VERSION ""

NS_ :

BS_:

BU_: BSG_Master Tester
VAL_TABLE_ IN_ANA_SELECT 1 "SEL2" 0 "SEL1" ;
VAL_TABLE_ SoundID 18 "TickTock" 17 "Gong3" 16 "800Hz" 15 "1250Hz" 14 "625Hz" 13 "Clack" 12 "Click" 11 "976Hz" 10 "2200Hz" 9 "1200Hz" 8 "488Hz" 7 "FireAlarm" 6 "Gong2" 5 "Gong1" 4 "600Hz" 3 "Tick" 2 "Tock" 1 "920Hz" 0 "2800Hz" ;

BO_ 2147484928 GATEWAY_TT_Ctrl_To_IC: 8 Tester
 SG_ N_Gateway : 0|64@1+ (1,0) [0|0] ""  BSG_Master

BO_ 2147484929 GATEWAY_Gauge_Ctrl_To_IC: 8 Tester
 SG_ N_Gateway : 0|64@1+ (1,0) [0|0] ""  BSG_Master

BO_ 2147484930 GATEWAY_Illumination_Ctrl_To_IC: 8 Tester
 SG_ N_Gateway : 0|64@1+ (1,0) [0|0] ""  BSG_Master

BO_ 2147484931 GATEWAY_Sound_Ctrl_To_IC: 8 Tester
 SG_ N_Gateway : 0|64@1+ (1,0) [0|0] ""  BSG_Master

BO_ 2147484932 GATEWAY_IC_Mode_To_IC: 8 Tester
 SG_ N_Gateway : 0|64@1+ (1,0) [0|0] ""  BSG_Master

BO_ 2147485184 GATEWAY_IC_Status_From_IC: 8 BSG_Master
 SG_ N_Gateway : 0|64@1+ (1,0) [0|0] ""  Tester

BO_ 2147486465 Out_Ctrl: 8 Tester
 SG_ WorkingMode : 60|1@1+ (1,0) [0|1] "" Vector__XXX
 SG_ Out_01_Ctrl : 0|1@1+ (1,0) [0|1] ""  BSG_Master
 SG_ Out_02_Ctrl : 1|1@1+ (1,0) [0|1] ""  BSG_Master
 SG_ Out_03_Ctrl : 2|1@1+ (1,0) [0|1] ""  BSG_Master
 SG_ Out_04_Ctrl : 3|1@1+ (1,0) [0|1] ""  BSG_Master
 SG_ Out_05_Ctrl : 4|1@1+ (1,0) [0|1] ""  BSG_Master
 SG_ Out_06_Ctrl : 5|1@1+ (1,0) [0|1] ""  BSG_Master
 SG_ Out_07_Ctrl : 6|1@1+ (1,0) [0|1] ""  BSG_Master
 SG_ Out_08_Ctrl : 7|1@1+ (1,0) [0|1] ""  BSG_Master
 SG_ Out_09_Ctrl : 8|1@1+ (1,0) [0|1] ""  BSG_Master
 SG_ Out_10_Ctrl : 9|1@1+ (1,0) [0|1] ""  BSG_Master
 SG_ Out_11_Ctrl : 10|1@1+ (1,0) [0|1] ""  BSG_Master
 SG_ Out_12_Ctrl : 11|1@1+ (1,0) [0|1] ""  BSG_Master
 SG_ Out_13_Ctrl : 12|1@1+ (1,0) [0|1] ""  BSG_Master
 SG_ Out_14_Ctrl : 13|1@1+ (1,0) [0|1] ""  BSG_Master
 SG_ Out_15_Ctrl : 14|1@1+ (1,0) [0|1] ""  BSG_Master
 SG_ Out_16_Ctrl : 15|1@1+ (1,0) [0|1] ""  BSG_Master
 SG_ Out_17_Ctrl : 16|1@1+ (1,0) [0|1] ""  BSG_Master
 SG_ Out_18_PWM_Ctrl : 24|8@1+ (1,0) [0|255] ""  BSG_Master
 SG_ Out_19_Ctrl : 18|1@1+ (1,0) [0|1] ""  BSG_Master
 SG_ Out_Supply_ANA_01_Ctrl : 56|1@1+ (1,0) [0|1] ""  BSG_Master
 SG_ Out_Supply_ANA_02_Ctrl : 57|1@1+ (1,0) [0|1] ""  BSG_Master
 SG_ Out_Supply_ANA_03_Ctrl : 58|1@1+ (1,0) [0|1] ""  BSG_Master

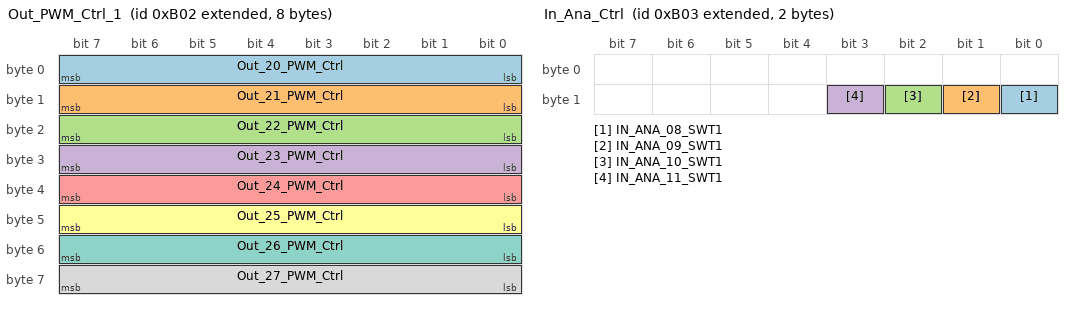
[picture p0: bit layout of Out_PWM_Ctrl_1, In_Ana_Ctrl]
BO_ 2147486466 Out_PWM_Ctrl_1: 8 Tester
 SG_ Out_20_PWM_Ctrl : 0|8@1+ (1,0) [0|255] ""  BSG_Master
 SG_ Out_21_PWM_Ctrl : 8|8@1+ (1,0) [0|255] ""  BSG_Master
 SG_ Out_22_PWM_Ctrl : 16|8@1+ (1,0) [0|255] ""  BSG_Master
 SG_ Out_23_PWM_Ctrl : 24|8@1+ (1,0) [0|255] ""  BSG_Master
 SG_ Out_24_PWM_Ctrl : 32|8@1+ (1,0) [0|255] ""  BSG_Master
 SG_ Out_25_PWM_Ctrl : 40|8@1+ (1,0) [0|255] ""  BSG_Master
 SG_ Out_26_PWM_Ctrl : 48|8@1+ (1,0) [0|255] ""  BSG_Master
 SG_ Out_27_PWM_Ctrl : 56|8@1+ (1,0) [0|255] ""  BSG_Master

BO_ 2147486467 In_Ana_Ctrl: 2 Tester
 SG_ IN_ANA_08_SWT1 : 8|1@1+ (1,0) [0|0] ""  BSG_Master
 SG_ IN_ANA_09_SWT1 : 9|1@1+ (1,0) [0|0] ""  BSG_Master
 SG_ IN_ANA_10_SWT1 : 10|1@1+ (1,0) [0|0] ""  BSG_Master
 SG_ IN_ANA_11_SWT1 : 11|1@1+ (1,0) [0|0] ""  BSG_Master

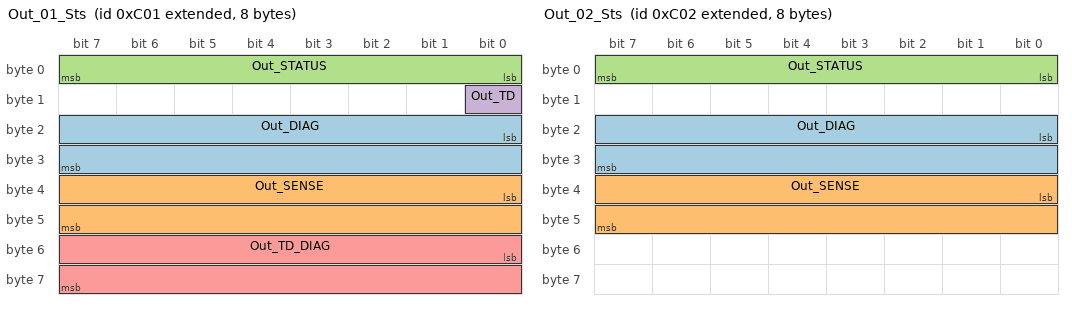
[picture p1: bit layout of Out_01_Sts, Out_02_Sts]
BO_ 2147486721 Out_01_Sts: 8 BSG_Master
 SG_ Out_DIAG : 16|16@1+ (1,0) [0|65535] ""  Tester
 SG_ Out_SENSE : 32|16@1+ (1,0) [0|65535] ""  Tester
 SG_ Out_STATUS : 0|8@1+ (1,0) [0|255] ""  Tester
 SG_ Out_TD : 8|1@1+ (1,0) [0|0] ""  Tester
 SG_ Out_TD_DIAG : 48|16@1+ (1,0) [0|0] ""  Tester

BO_ 2147486722 Out_02_Sts: 8 BSG_Master
 SG_ Out_DIAG : 16|16@1+ (1,0) [0|65535] ""  Tester
 SG_ Out_SENSE : 32|16@1+ (1,0) [0|65535] ""  Tester
 SG_ Out_STATUS : 0|8@1+ (1,0) [0|255] ""  Tester

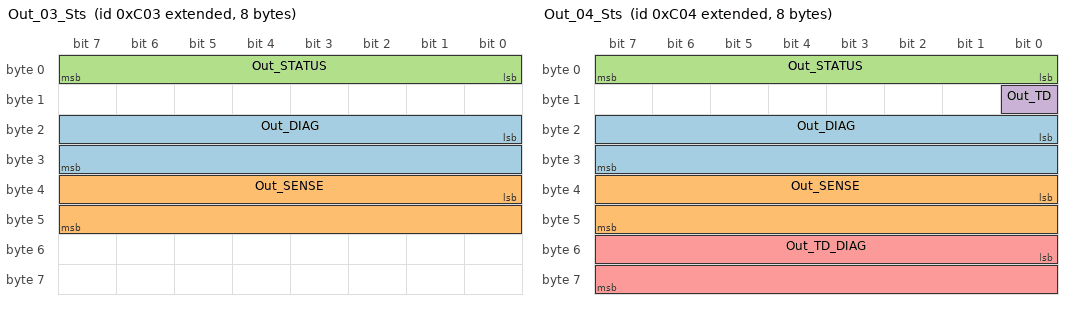
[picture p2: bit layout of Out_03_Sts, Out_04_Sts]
BO_ 2147486723 Out_03_Sts: 8 BSG_Master
 SG_ Out_DIAG : 16|16@1+ (1,0) [0|65535] ""  Tester
 SG_ Out_SENSE : 32|16@1+ (1,0) [0|65535] ""  Tester
 SG_ Out_STATUS : 0|8@1+ (1,0) [0|255] ""  Tester

BO_ 2147486724 Out_04_Sts: 8 BSG_Master
 SG_ Out_DIAG : 16|16@1+ (1,0) [0|65535] ""  Tester
 SG_ Out_SENSE : 32|16@1+ (1,0) [0|65535] ""  Tester
 SG_ Out_STATUS : 0|8@1+ (1,0) [0|255] ""  Tester
 SG_ Out_TD : 8|1@1+ (1,0) [0|0] ""  Tester
 SG_ Out_TD_DIAG : 48|16@1+ (1,0) [0|0] ""  Tester

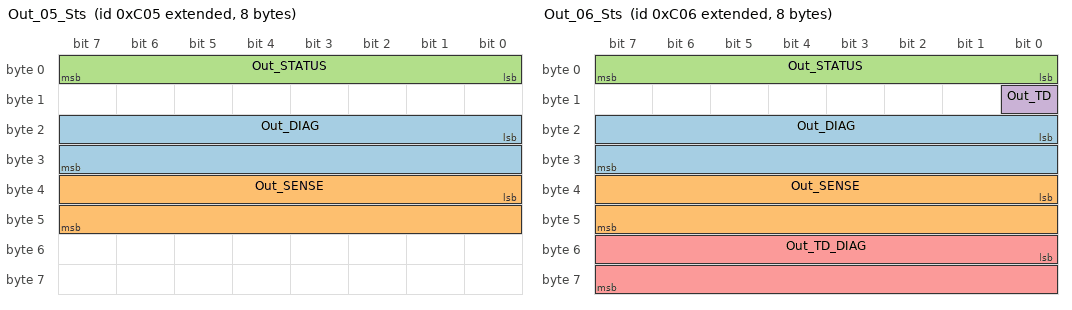
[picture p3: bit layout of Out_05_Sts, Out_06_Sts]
BO_ 2147486725 Out_05_Sts: 8 BSG_Master
 SG_ Out_DIAG : 16|16@1+ (1,0) [0|65535] ""  Tester
 SG_ Out_SENSE : 32|16@1+ (1,0) [0|65535] ""  Tester
 SG_ Out_STATUS : 0|8@1+ (1,0) [0|255] ""  Tester

BO_ 2147486726 Out_06_Sts: 8 BSG_Master
 SG_ Out_DIAG : 16|16@1+ (1,0) [0|65535] ""  Tester
 SG_ Out_SENSE : 32|16@1+ (1,0) [0|65535] ""  Tester
 SG_ Out_STATUS : 0|8@1+ (1,0) [0|255] ""  Tester
 SG_ Out_TD : 8|1@1+ (1,0) [0|0] ""  Tester
 SG_ Out_TD_DIAG : 48|16@1+ (1,0) [0|0] ""  Tester

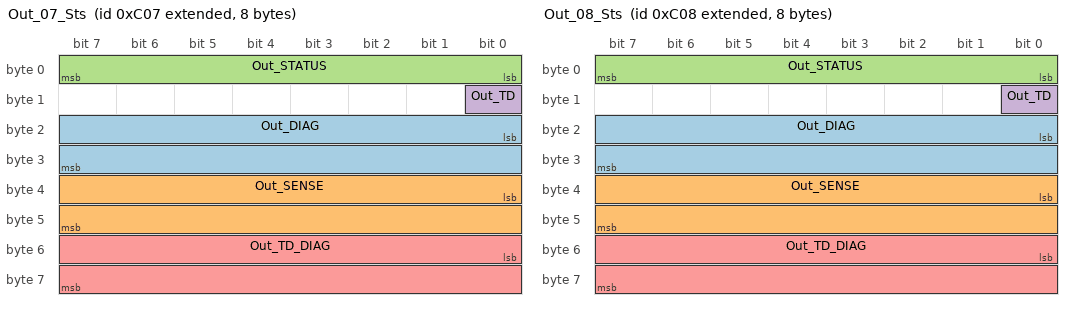
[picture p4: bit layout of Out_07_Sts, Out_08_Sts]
BO_ 2147486727 Out_07_Sts: 8 BSG_Master
 SG_ Out_DIAG : 16|16@1+ (1,0) [0|65535] ""  Tester
 SG_ Out_SENSE : 32|16@1+ (1,0) [0|65535] ""  Tester
 SG_ Out_STATUS : 0|8@1+ (1,0) [0|255] ""  Tester
 SG_ Out_TD : 8|1@1+ (1,0) [0|0] ""  Tester
 SG_ Out_TD_DIAG : 48|16@1+ (1,0) [0|0] ""  Tester

BO_ 2147486728 Out_08_Sts: 8 BSG_Master
 SG_ Out_DIAG : 16|16@1+ (1,0) [0|65535] ""  Tester
 SG_ Out_SENSE : 32|16@1+ (1,0) [0|65535] ""  Tester
 SG_ Out_STATUS : 0|8@1+ (1,0) [0|255] ""  Tester
 SG_ Out_TD : 8|1@1+ (1,0) [0|0] ""  Tester
 SG_ Out_TD_DIAG : 48|16@1+ (1,0) [0|0] ""  Tester

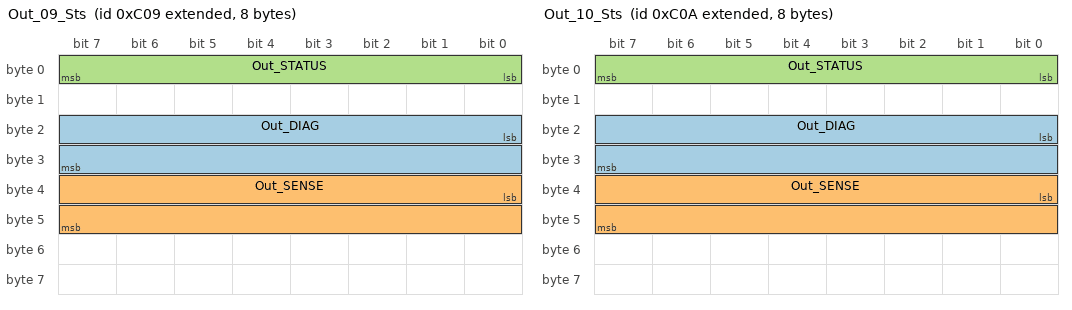
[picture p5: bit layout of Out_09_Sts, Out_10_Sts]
BO_ 2147486729 Out_09_Sts: 8 BSG_Master
 SG_ Out_DIAG : 16|16@1+ (1,0) [0|65535] ""  Tester
 SG_ Out_SENSE : 32|16@1+ (1,0) [0|65535] ""  Tester
 SG_ Out_STATUS : 0|8@1+ (1,0) [0|255] ""  Tester

BO_ 2147486730 Out_10_Sts: 8 BSG_Master
 SG_ Out_DIAG : 16|16@1+ (1,0) [0|65535] ""  Tester
 SG_ Out_SENSE : 32|16@1+ (1,0) [0|65535] ""  Tester
 SG_ Out_STATUS : 0|8@1+ (1,0) [0|255] ""  Tester

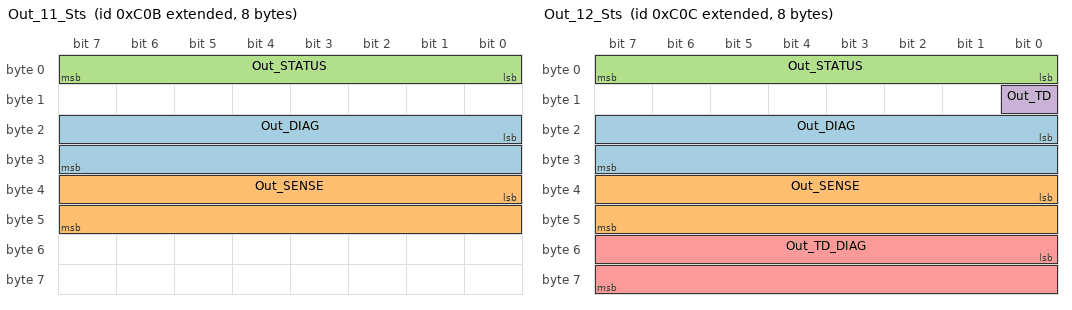
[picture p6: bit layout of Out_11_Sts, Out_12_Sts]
BO_ 2147486731 Out_11_Sts: 8 BSG_Master
 SG_ Out_DIAG : 16|16@1+ (1,0) [0|65535] ""  Tester
 SG_ Out_SENSE : 32|16@1+ (1,0) [0|65535] ""  Tester
 SG_ Out_STATUS : 0|8@1+ (1,0) [0|255] ""  Tester

BO_ 2147486732 Out_12_Sts: 8 BSG_Master
 SG_ Out_DIAG : 16|16@1+ (1,0) [0|65535] ""  Tester
 SG_ Out_SENSE : 32|16@1+ (1,0) [0|65535] ""  Tester
 SG_ Out_STATUS : 0|8@1+ (1,0) [0|255] ""  Tester
 SG_ Out_TD : 8|1@1+ (1,0) [0|0] ""  Tester
 SG_ Out_TD_DIAG : 48|16@1+ (1,0) [0|0] ""  Tester

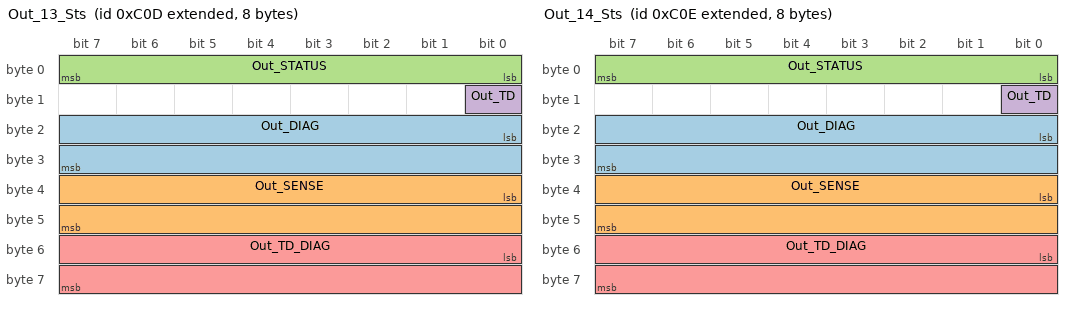
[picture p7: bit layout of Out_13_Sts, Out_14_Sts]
BO_ 2147486733 Out_13_Sts: 8 BSG_Master
 SG_ Out_DIAG : 16|16@1+ (1,0) [0|65535] ""  Tester
 SG_ Out_SENSE : 32|16@1+ (1,0) [0|65535] ""  Tester
 SG_ Out_STATUS : 0|8@1+ (1,0) [0|255] ""  Tester
 SG_ Out_TD : 8|1@1+ (1,0) [0|0] ""  Tester
 SG_ Out_TD_DIAG : 48|16@1+ (1,0) [0|0] ""  Tester

BO_ 2147486734 Out_14_Sts: 8 BSG_Master
 SG_ Out_DIAG : 16|16@1+ (1,0) [0|65535] ""  Tester
 SG_ Out_SENSE : 32|16@1+ (1,0) [0|65535] ""  Tester
 SG_ Out_STATUS : 0|8@1+ (1,0) [0|255] ""  Tester
 SG_ Out_TD : 8|1@1+ (1,0) [0|0] ""  Tester
 SG_ Out_TD_DIAG : 48|16@1+ (1,0) [0|0] ""  Tester

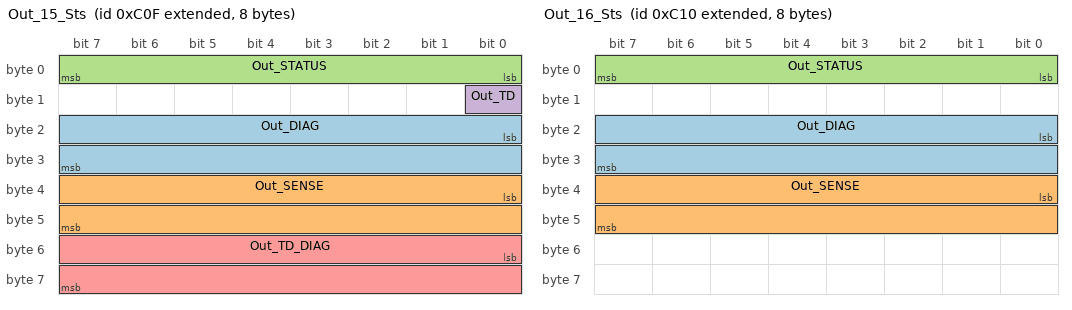
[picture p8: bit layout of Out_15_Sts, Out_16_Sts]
BO_ 2147486735 Out_15_Sts: 8 BSG_Master
 SG_ Out_DIAG : 16|16@1+ (1,0) [0|65535] ""  Tester
 SG_ Out_SENSE : 32|16@1+ (1,0) [0|65535] ""  Tester
 SG_ Out_STATUS : 0|8@1+ (1,0) [0|255] ""  Tester
 SG_ Out_TD : 8|1@1+ (1,0) [0|0] ""  Tester
 SG_ Out_TD_DIAG : 48|16@1+ (1,0) [0|0] ""  Tester

BO_ 2147486736 Out_16_Sts: 8 BSG_Master
 SG_ Out_DIAG : 16|16@1+ (1,0) [0|65535] ""  Tester
 SG_ Out_SENSE : 32|16@1+ (1,0) [0|65535] ""  Tester
 SG_ Out_STATUS : 0|8@1+ (1,0) [0|255] ""  Tester

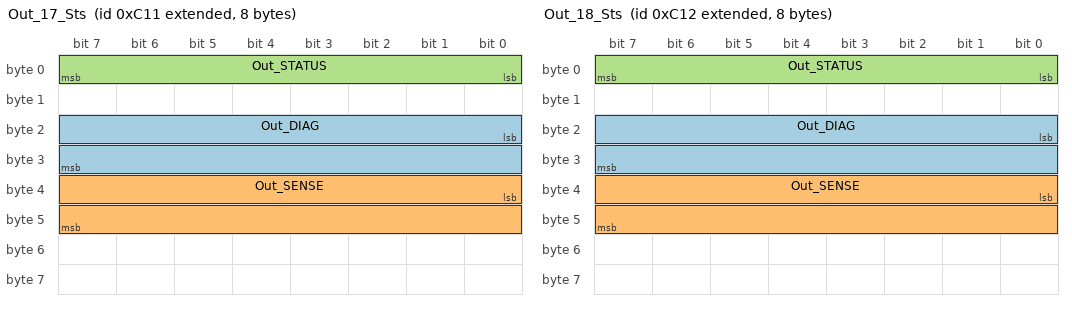
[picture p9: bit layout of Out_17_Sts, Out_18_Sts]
BO_ 2147486737 Out_17_Sts: 8 BSG_Master
 SG_ Out_DIAG : 16|16@1+ (1,0) [0|65535] ""  Tester
 SG_ Out_SENSE : 32|16@1+ (1,0) [0|65535] ""  Tester
 SG_ Out_STATUS : 0|8@1+ (1,0) [0|255] ""  Tester

BO_ 2147486738 Out_18_Sts: 8 BSG_Master
 SG_ Out_DIAG : 16|16@1+ (1,0) [0|65535] ""  Tester
 SG_ Out_SENSE : 32|16@1+ (1,0) [0|65535] ""  Tester
 SG_ Out_STATUS : 0|8@1+ (1,0) [0|255] ""  Tester

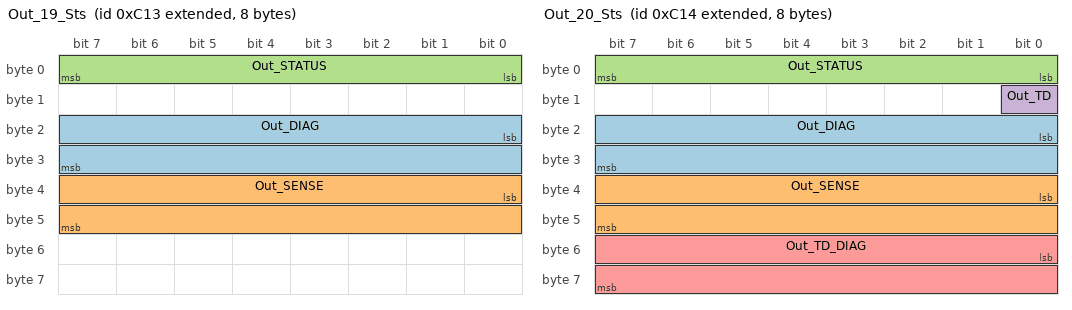
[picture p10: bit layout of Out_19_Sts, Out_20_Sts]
BO_ 2147486739 Out_19_Sts: 8 BSG_Master
 SG_ Out_DIAG : 16|16@1+ (1,0) [0|65535] ""  Tester
 SG_ Out_SENSE : 32|16@1+ (1,0) [0|65535] ""  Tester
 SG_ Out_STATUS : 0|8@1+ (1,0) [0|255] ""  Tester

BO_ 2147486740 Out_20_Sts: 8 BSG_Master
 SG_ Out_DIAG : 16|16@1+ (1,0) [0|65535] ""  Tester
 SG_ Out_SENSE : 32|16@1+ (1,0) [0|65535] ""  Tester
 SG_ Out_STATUS : 0|8@1+ (1,0) [0|255] ""  Tester
 SG_ Out_TD : 8|1@1+ (1,0) [0|0] ""  Tester
 SG_ Out_TD_DIAG : 48|16@1+ (1,0) [0|0] ""  Tester

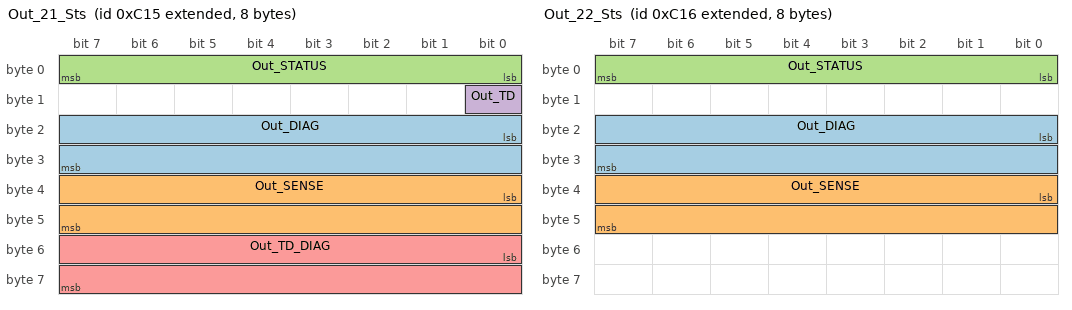
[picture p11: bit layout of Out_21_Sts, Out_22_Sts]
BO_ 2147486741 Out_21_Sts: 8 BSG_Master
 SG_ Out_DIAG : 16|16@1+ (1,0) [0|65535] ""  Tester
 SG_ Out_SENSE : 32|16@1+ (1,0) [0|65535] ""  Tester
 SG_ Out_STATUS : 0|8@1+ (1,0) [0|255] ""  Tester
 SG_ Out_TD : 8|1@1+ (1,0) [0|0] ""  Tester
 SG_ Out_TD_DIAG : 48|16@1+ (1,0) [0|0] ""  Tester

BO_ 2147486742 Out_22_Sts: 8 BSG_Master
 SG_ Out_DIAG : 16|16@1+ (1,0) [0|65535] ""  Tester
 SG_ Out_SENSE : 32|16@1+ (1,0) [0|65535] ""  Tester
 SG_ Out_STATUS : 0|8@1+ (1,0) [0|255] ""  Tester

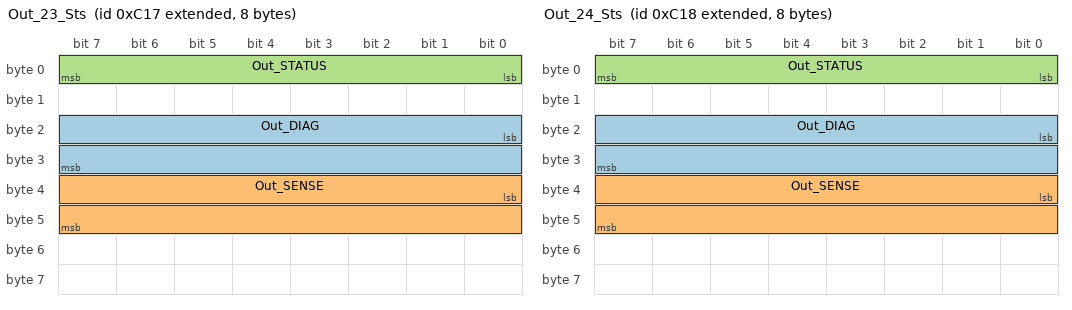
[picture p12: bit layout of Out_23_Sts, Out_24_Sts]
BO_ 2147486743 Out_23_Sts: 8 BSG_Master
 SG_ Out_DIAG : 16|16@1+ (1,0) [0|65535] ""  Tester
 SG_ Out_SENSE : 32|16@1+ (1,0) [0|65535] ""  Tester
 SG_ Out_STATUS : 0|8@1+ (1,0) [0|255] ""  Tester

BO_ 2147486744 Out_24_Sts: 8 BSG_Master
 SG_ Out_DIAG : 16|16@1+ (1,0) [0|65535] ""  Tester
 SG_ Out_SENSE : 32|16@1+ (1,0) [0|65535] ""  Tester
 SG_ Out_STATUS : 0|8@1+ (1,0) [0|255] ""  Tester

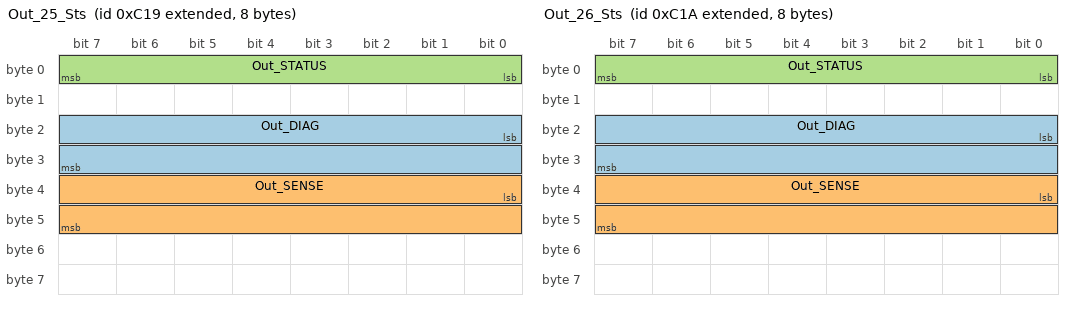
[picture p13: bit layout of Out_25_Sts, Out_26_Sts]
BO_ 2147486745 Out_25_Sts: 8 BSG_Master
 SG_ Out_DIAG : 16|16@1+ (1,0) [0|65535] ""  Tester
 SG_ Out_SENSE : 32|16@1+ (1,0) [0|65535] ""  Tester
 SG_ Out_STATUS : 0|8@1+ (1,0) [0|255] ""  Tester

BO_ 2147486746 Out_26_Sts: 8 BSG_Master
 SG_ Out_DIAG : 16|16@1+ (1,0) [0|65535] ""  Tester
 SG_ Out_SENSE : 32|16@1+ (1,0) [0|65535] ""  Tester
 SG_ Out_STATUS : 0|8@1+ (1,0) [0|255] ""  Tester

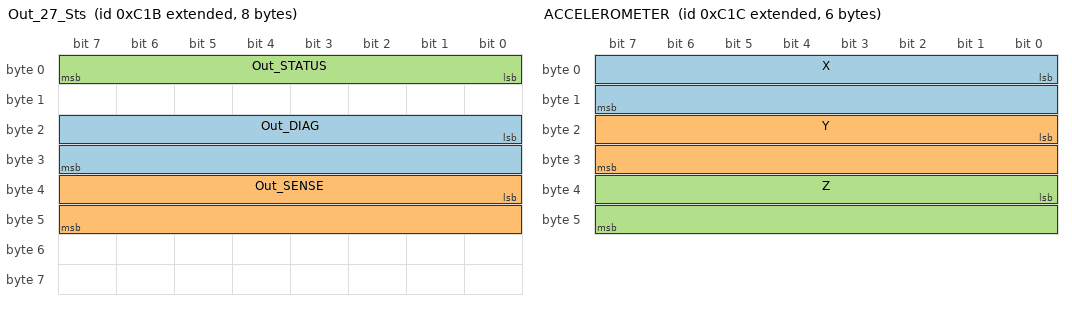
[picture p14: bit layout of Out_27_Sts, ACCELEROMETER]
BO_ 2147486747 Out_27_Sts: 8 BSG_Master
 SG_ Out_DIAG : 16|16@1+ (1,0) [0|65535] ""  Tester
 SG_ Out_SENSE : 32|16@1+ (1,0) [0|65535] ""  Tester
 SG_ Out_STATUS : 0|8@1+ (1,0) [0|255] ""  Tester

BO_ 2147486748 ACCELEROMETER: 6 BSG_Master
 SG_ X : 0|16@1- (1,0) [0|0] ""  Tester
 SG_ Y : 16|16@1- (1,0) [0|0] ""  Tester
 SG_ Z : 32|16@1- (1,0) [0|0] ""  Tester

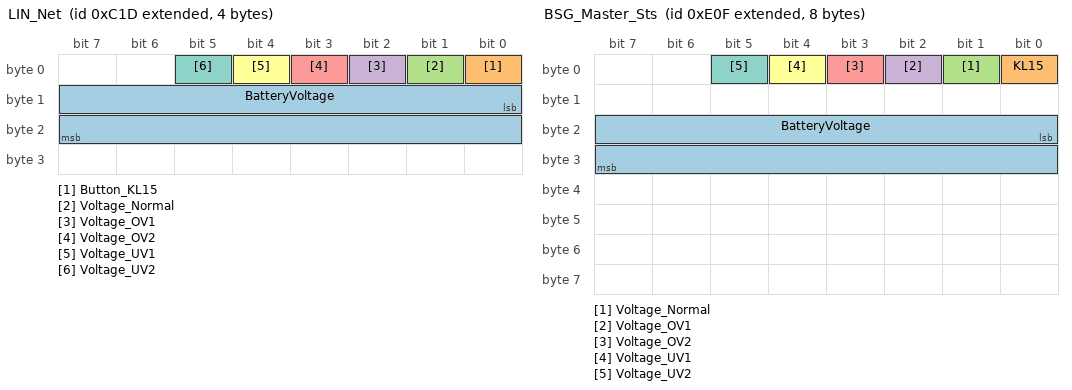
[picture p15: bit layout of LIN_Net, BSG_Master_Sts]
BO_ 2147486749 LIN_Net: 4 BSG_Master
 SG_ BatteryVoltage : 8|16@1+ (1,0) [0|0] ""  Tester
 SG_ Button_KL15 : 0|1@1+ (1,0) [0|0] ""  Tester
 SG_ Voltage_Normal : 1|1@1+ (1,0) [0|0] ""  Tester
 SG_ Voltage_OV1 : 2|1@1+ (1,0) [0|0] ""  Tester
 SG_ Voltage_OV2 : 3|1@1+ (1,0) [0|0] ""  Tester
 SG_ Voltage_UV1 : 4|1@1+ (1,0) [0|1] ""  Tester
 SG_ Voltage_UV2 : 5|1@1+ (1,0) [0|1] ""  Tester

BO_ 2147486750 Out_Supply_ANA_01_Sts: 8 BSG_Master
 SG_ Supply_ANA_DIAG : 16|16@1+ (1,0) [0|65535] ""  Tester
 SG_ Supply_ANA_Val : 0|16@1+ (1,0) [0|65535] ""  Tester

BO_ 2147486751 Out_Supply_ANA_02_Sts: 8 BSG_Master
 SG_ Supply_ANA_DIAG : 16|16@1+ (1,0) [0|65535] ""  Tester
 SG_ Supply_ANA_Val : 0|16@1+ (1,0) [0|65535] ""  Tester

BO_ 2147486752 Out_Supply_ANA_03_Sts: 8 BSG_Master
 SG_ Supply_ANA_DIAG : 16|16@1+ (1,0) [0|65535] ""  Tester
 SG_ Supply_ANA_Val : 0|16@1+ (1,0) [0|65535] ""  Tester

BO_ 2147486977 In_Dig_01_Sts: 8 BSG_Master
 SG_ IN_DIG_DIAG : 16|16@1+ (1,0) [0|65535] ""  Tester
 SG_ IN_DIG_Val : 0|1@1+ (1,0) [0|1] ""  Tester

BO_ 2147486978 In_Dig_02_Sts: 8 BSG_Master
 SG_ IN_DIG_DIAG : 16|16@1+ (1,0) [0|65535] ""  Tester
 SG_ IN_DIG_Val : 0|1@1+ (1,0) [0|1] ""  Tester

BO_ 2147486979 In_Dig_03_Sts: 8 BSG_Master
 SG_ IN_DIG_DIAG : 16|16@1+ (1,0) [0|65535] ""  Tester
 SG_ IN_DIG_Val : 0|1@1+ (1,0) [0|1] ""  Tester

BO_ 2147486980 In_Dig_04_Sts: 8 BSG_Master
 SG_ IN_DIG_DIAG : 16|16@1+ (1,0) [0|65535] ""  Tester
 SG_ IN_DIG_Val : 0|1@1+ (1,0) [0|1] ""  Tester

BO_ 2147486981 In_Dig_05_Sts: 8 BSG_Master
 SG_ IN_DIG_DIAG : 16|16@1+ (1,0) [0|65535] ""  Tester
 SG_ IN_DIG_Val : 0|1@1+ (1,0) [0|1] ""  Tester

BO_ 2147486982 In_Dig_06_Sts: 8 BSG_Master
 SG_ IN_DIG_DIAG : 16|16@1+ (1,0) [0|65535] ""  Tester
 SG_ IN_DIG_Val : 0|1@1+ (1,0) [0|1] ""  Tester

BO_ 2147486983 In_Dig_07_Sts: 8 BSG_Master
 SG_ IN_DIG_DIAG : 16|16@1+ (1,0) [0|65535] ""  Tester
 SG_ IN_DIG_Val : 0|1@1+ (1,0) [0|1] ""  Tester

BO_ 2147486984 In_Dig_08_Sts: 8 BSG_Master
 SG_ IN_DIG_DIAG : 16|16@1+ (1,0) [0|65535] ""  Tester
 SG_ IN_DIG_Val : 0|1@1+ (1,0) [0|1] ""  Tester

BO_ 2147486985 In_Dig_09_Sts: 8 BSG_Master
 SG_ IN_DIG_DIAG : 16|16@1+ (1,0) [0|65535] ""  Tester
 SG_ IN_DIG_Val : 0|1@1+ (1,0) [0|1] ""  Tester

BO_ 2147486986 In_Dig_10_Sts: 8 BSG_Master
 SG_ IN_DIG_DIAG : 16|16@1+ (1,0) [0|65535] ""  Tester
 SG_ IN_DIG_Val : 0|1@1+ (1,0) [0|1] ""  Tester

BO_ 2147486987 In_Dig_11_Sts: 8 BSG_Master
 SG_ IN_DIG_DIAG : 16|16@1+ (1,0) [0|65535] ""  Tester
 SG_ IN_DIG_Val : 0|1@1+ (1,0) [0|1] ""  Tester

BO_ 2147486988 In_Dig_12_Sts: 8 BSG_Master
 SG_ IN_DIG_DIAG : 16|16@1+ (1,0) [0|65535] ""  Tester
 SG_ IN_DIG_Val : 0|1@1+ (1,0) [0|1] ""  Tester

BO_ 2147486989 In_Dig_13_Sts: 8 BSG_Master
 SG_ IN_DIG_DIAG : 16|16@1+ (1,0) [0|65535] ""  Tester
 SG_ IN_DIG_Val : 0|1@1+ (1,0) [0|1] ""  Tester

BO_ 2147486990 In_Dig_14_Sts: 8 BSG_Master
 SG_ IN_DIG_DIAG : 16|16@1+ (1,0) [0|65535] ""  Tester
 SG_ IN_DIG_Val : 0|1@1+ (1,0) [0|1] ""  Tester

BO_ 2147486991 In_Dig_15_Sts: 8 BSG_Master
 SG_ IN_DIG_DIAG : 16|16@1+ (1,0) [0|65535] ""  Tester
 SG_ IN_DIG_Val : 0|1@1+ (1,0) [0|1] ""  Tester

BO_ 2147486992 In_Dig_16_Sts: 8 BSG_Master
 SG_ IN_DIG_DIAG : 16|16@1+ (1,0) [0|65535] ""  Tester
 SG_ IN_DIG_Val : 0|1@1+ (1,0) [0|1] ""  Tester

BO_ 2147486993 In_Dig_17_Sts: 8 BSG_Master
 SG_ IN_DIG_DIAG : 16|16@1+ (1,0) [0|65535] ""  Tester
 SG_ IN_DIG_Val : 0|1@1+ (1,0) [0|1] ""  Tester

BO_ 2147486994 In_Dig_18_Sts: 8 BSG_Master
 SG_ IN_DIG_DIAG : 16|16@1+ (1,0) [0|65535] ""  Tester
 SG_ IN_DIG_Val : 0|1@1+ (1,0) [0|1] ""  Tester

BO_ 2147486995 In_Dig_19_Sts: 8 BSG_Master
 SG_ IN_DIG_DIAG : 16|16@1+ (1,0) [0|65535] ""  Tester
 SG_ IN_DIG_Val : 0|1@1+ (1,0) [0|1] ""  Tester

BO_ 2147486996 In_Dig_20_Sts: 8 BSG_Master
 SG_ IN_DIG_DIAG : 16|16@1+ (1,0) [0|65535] ""  Tester
 SG_ IN_DIG_Val : 0|1@1+ (1,0) [0|1] ""  Tester

BO_ 2147486997 In_Dig_21_Sts: 8 BSG_Master
 SG_ IN_DIG_DIAG : 16|16@1+ (1,0) [0|65535] ""  Tester
 SG_ IN_DIG_Val : 0|1@1+ (1,0) [0|1] ""  Tester

BO_ 2147486998 In_Dig_22_Sts: 8 BSG_Master
 SG_ IN_DIG_DIAG : 16|16@1+ (1,0) [0|65535] ""  Tester
 SG_ IN_DIG_Val : 0|1@1+ (1,0) [0|1] ""  Tester

BO_ 2147486999 In_Dig_23_Sts: 8 BSG_Master
 SG_ IN_DIG_DIAG : 16|16@1+ (1,0) [0|65535] ""  Tester
 SG_ IN_DIG_Val : 0|1@1+ (1,0) [0|1] ""  Tester

BO_ 2147487000 In_Dig_24_Sts: 8 BSG_Master
 SG_ IN_DIG_DIAG : 16|16@1+ (1,0) [0|65535] ""  Tester
 SG_ IN_DIG_Val : 0|1@1+ (1,0) [0|1] ""  Tester

BO_ 2147487001 In_Dig_25_Sts: 8 BSG_Master
 SG_ IN_DIG_DIAG : 16|16@1+ (1,0) [0|65535] ""  Tester
 SG_ IN_DIG_Val : 0|1@1+ (1,0) [0|1] ""  Tester

BO_ 2147487002 In_Dig_26_Sts: 8 BSG_Master
 SG_ IN_DIG_DIAG : 16|16@1+ (1,0) [0|65535] ""  Tester
 SG_ IN_DIG_Val : 0|1@1+ (1,0) [0|1] ""  Tester

BO_ 2147487003 In_Dig_27_Sts: 8 BSG_Master
 SG_ IN_DIG_DIAG : 16|16@1+ (1,0) [0|65535] ""  Tester
 SG_ IN_DIG_Val : 0|1@1+ (1,0) [0|1] ""  Tester

BO_ 2147487004 In_Dig_28_Sts: 8 BSG_Master
 SG_ IN_DIG_DIAG : 16|16@1+ (1,0) [0|65535] ""  Tester
 SG_ IN_DIG_Val : 0|1@1+ (1,0) [0|1] ""  Tester

BO_ 2147487005 In_Dig_29_Sts: 8 BSG_Master
 SG_ IN_DIG_DIAG : 16|16@1+ (1,0) [0|65535] ""  Tester
 SG_ IN_DIG_Val : 0|1@1+ (1,0) [0|1] ""  Tester

BO_ 2147487006 In_Dig_30_Sts: 8 BSG_Master
 SG_ IN_DIG_DIAG : 16|16@1+ (1,0) [0|65535] ""  Tester
 SG_ IN_DIG_Val : 0|1@1+ (1,0) [0|1] ""  Tester

BO_ 2147487007 In_Dig_31_Sts: 8 BSG_Master
 SG_ IN_DIG_DIAG : 16|16@1+ (1,0) [0|65535] ""  Tester
 SG_ IN_DIG_Val : 0|1@1+ (1,0) [0|1] ""  Tester

BO_ 2147487008 In_Dig_32_Sts: 8 BSG_Master
 SG_ IN_DIG_DIAG : 16|16@1+ (1,0) [0|65535] ""  Tester
 SG_ IN_DIG_Val : 0|1@1+ (1,0) [0|1] ""  Tester

BO_ 2147487009 In_Dig_33_Sts: 8 BSG_Master
 SG_ IN_DIG_DIAG : 16|16@1+ (1,0) [0|65535] ""  Tester
 SG_ IN_DIG_Val : 0|1@1+ (1,0) [0|1] ""  Tester

BO_ 2147487010 In_Dig_34_Sts: 8 BSG_Master
 SG_ IN_DIG_DIAG : 16|16@1+ (1,0) [0|65535] ""  Tester
 SG_ IN_DIG_Val : 0|1@1+ (1,0) [0|1] ""  Tester

BO_ 2147487011 In_Dig_35_Sts: 8 BSG_Master
 SG_ IN_DIG_DIAG : 16|16@1+ (1,0) [0|65535] ""  Tester
 SG_ IN_DIG_Val : 0|1@1+ (1,0) [0|1] ""  Tester

BO_ 2147487012 In_Dig_36_Sts: 8 BSG_Master
 SG_ IN_DIG_DIAG : 16|16@1+ (1,0) [0|65535] ""  Tester
 SG_ IN_DIG_Val : 0|1@1+ (1,0) [0|1] ""  Tester

BO_ 2147487013 In_Dig_37_Sts: 8 BSG_Master
 SG_ IN_DIG_DIAG : 16|16@1+ (1,0) [0|65535] ""  Tester
 SG_ IN_DIG_Val : 0|1@1+ (1,0) [0|1] ""  Tester

BO_ 2147487014 In_Dig_38_Sts: 8 BSG_Master
 SG_ IN_DIG_DIAG : 16|16@1+ (1,0) [0|65535] ""  Tester
 SG_ IN_DIG_Val : 0|1@1+ (1,0) [0|1] ""  Tester

BO_ 2147487015 In_Dig_39_Sts: 8 BSG_Master
 SG_ IN_DIG_DIAG : 16|16@1+ (1,0) [0|65535] ""  Tester
 SG_ IN_DIG_Val : 0|1@1+ (1,0) [0|1] ""  Tester

BO_ 2147487016 In_Dig_40_Sts: 8 BSG_Master
 SG_ IN_DIG_DIAG : 16|16@1+ (1,0) [0|65535] ""  Tester
 SG_ IN_DIG_Val : 0|1@1+ (1,0) [0|1] ""  Tester

BO_ 2147487017 In_Dig_41_Sts: 8 BSG_Master
 SG_ IN_DIG_DIAG : 16|16@1+ (1,0) [0|65535] ""  Tester
 SG_ IN_DIG_Val : 0|1@1+ (1,0) [0|1] ""  Tester

BO_ 2147487018 In_Dig_42_Sts: 8 BSG_Master
 SG_ IN_DIG_DIAG : 16|16@1+ (1,0) [0|65535] ""  Tester
 SG_ IN_DIG_Val : 0|1@1+ (1,0) [0|1] ""  Tester

BO_ 2147487019 In_Dig_43_Sts: 8 BSG_Master
 SG_ IN_DIG_DIAG : 16|16@1+ (1,0) [0|65535] ""  Tester
 SG_ IN_DIG_Val : 0|1@1+ (1,0) [0|1] ""  Tester

BO_ 2147487020 In_Dig_44_Sts: 8 BSG_Master
 SG_ IN_DIG_DIAG : 16|16@1+ (1,0) [0|65535] ""  Tester
 SG_ IN_DIG_Val : 0|1@1+ (1,0) [0|1] ""  Tester

BO_ 2147487021 In_Dig_45_Sts: 8 BSG_Master
 SG_ IN_DIG_DIAG : 16|16@1+ (1,0) [0|65535] ""  Tester
 SG_ IN_DIG_Val : 0|1@1+ (1,0) [0|1] ""  Tester

BO_ 2147487022 In_Dig_46_Sts: 8 BSG_Master
 SG_ IN_DIG_DIAG : 16|16@1+ (1,0) [0|65535] ""  Tester
 SG_ IN_DIG_Val : 0|1@1+ (1,0) [0|1] ""  Tester

BO_ 2147487024 In_Dig_48_Sts: 8 BSG_Master
 SG_ IN_DIG_DIAG : 16|16@1+ (1,0) [0|65535] ""  Tester
 SG_ IN_DIG_Val : 0|1@1+ (1,0) [0|1] ""  Tester

BO_ 2147487025 In_Dig_49_Sts: 8 BSG_Master
 SG_ IN_DIG_DIAG : 16|16@1+ (1,0) [0|65535] ""  Tester
 SG_ IN_DIG_Val : 0|1@1+ (1,0) [0|1] ""  Tester

BO_ 2147487026 In_Dig_50_Sts: 8 BSG_Master
 SG_ IN_DIG_DIAG : 16|16@1+ (1,0) [0|65535] ""  Tester
 SG_ IN_DIG_Val : 0|1@1+ (1,0) [0|1] ""  Tester

BO_ 2147487232 PWR_Sts: 8 BSG_Master
 SG_ PWR_DIAG : 32|16@1+ (1,0) [0|65535] ""  Tester
 SG_ PWR_Val : 0|32@1+ (1,0) [0|4294967295] ""  Tester

BO_ 2147487233 PWR_G1_Sts: 8 BSG_Master
 SG_ PWR_Gx_DIAG : 16|16@1+ (1,0) [0|65535] ""  Tester
 SG_ PWR_Gx_Val : 0|16@1+ (1,0) [0|65535] ""  Tester

BO_ 2147487234 PWR_G2_Sts: 8 BSG_Master
 SG_ PWR_Gx_DIAG : 16|16@1+ (1,0) [0|65535] ""  Tester
 SG_ PWR_Gx_Val : 0|16@1+ (1,0) [0|65535] ""  Tester

BO_ 2147487235 PWR_G3_Sts: 8 BSG_Master
 SG_ PWR_Gx_DIAG : 16|16@1+ (1,0) [0|65535] ""  Tester
 SG_ PWR_Gx_Val : 0|16@1+ (1,0) [0|65535] ""  Tester

BO_ 2147487236 PWR_G4_Sts: 8 BSG_Master
 SG_ PWR_Gx_DIAG : 16|16@1+ (1,0) [0|65535] ""  Tester
 SG_ PWR_Gx_Val : 0|16@1+ (1,0) [0|65535] ""  Tester

BO_ 2147487237 PWR_G5_Sts: 8 BSG_Master
 SG_ PWR_Gx_DIAG : 16|16@1+ (1,0) [0|65535] ""  Tester
 SG_ PWR_Gx_Val : 0|16@1+ (1,0) [0|65535] ""  Tester

BO_ 2147487239 PWR_G7_Sts: 8 BSG_Master
 SG_ PWR_Gx_DIAG : 16|16@1+ (1,0) [0|65535] ""  Tester
 SG_ PWR_Gx_Val : 0|16@1+ (1,0) [0|65535] ""  Tester

BO_ 2147487247 BSG_Master_Sts: 8 BSG_Master
 SG_ BatteryVoltage : 16|16@1+ (1,0) [0|65535] ""  Tester
 SG_ KL15 : 0|1@1+ (1,0) [0|1] ""  Tester
 SG_ Voltage_Normal : 1|1@1+ (1,0) [0|1] ""  Tester
 SG_ Voltage_OV1 : 2|1@1+ (1,0) [0|1] ""  Tester
 SG_ Voltage_OV2 : 3|1@1+ (1,0) [0|1] ""  Tester
 SG_ Voltage_UV1 : 4|1@1+ (1,0) [0|1] ""  Tester
 SG_ Voltage_UV2 : 5|1@1+ (1,0) [0|1] ""  Tester

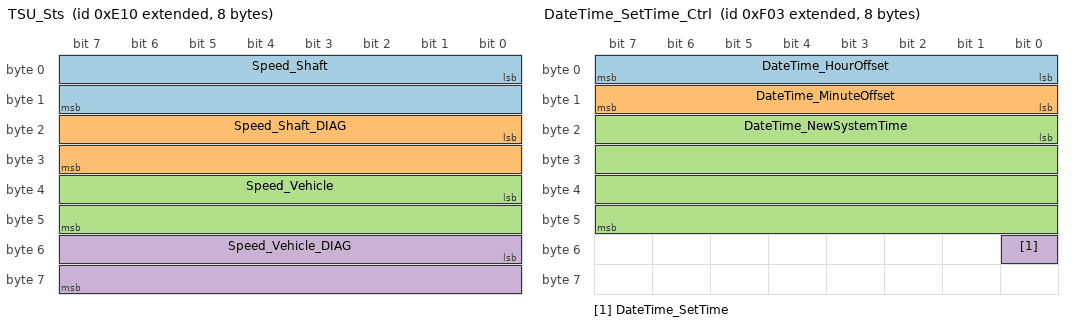
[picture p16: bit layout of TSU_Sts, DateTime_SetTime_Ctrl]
BO_ 2147487248 TSU_Sts: 8 BSG_Master
 SG_ Speed_Shaft : 0|16@1+ (1,0) [0|65535] ""  Tester
 SG_ Speed_Shaft_DIAG : 16|16@1+ (1,0) [0|65535] ""  Tester
 SG_ Speed_Vehicle : 32|16@1+ (1,0) [0|65535] ""  Tester
 SG_ Speed_Vehicle_DIAG : 48|16@1+ (1,0) [0|65535] ""  Tester

BO_ 2147487249 In_Ana_01_Sts: 8 BSG_Master
 SG_ IN_ANA_DIAG : 32|16@1+ (1,0) [0|65535] ""  Tester
 SG_ IN_ANA_Val : 0|32@1+ (1,0) [0|4294967295] ""  Tester

BO_ 2147487250 In_Ana_02_Sts: 8 BSG_Master
 SG_ IN_ANA_DIAG : 32|16@1+ (1,0) [0|65535] ""  Tester
 SG_ IN_ANA_Val : 0|32@1+ (1,0) [0|4294967295] ""  Tester

BO_ 2147487251 In_Ana_03_Sts: 8 BSG_Master
 SG_ IN_ANA_DIAG : 32|16@1+ (1,0) [0|65535] ""  Tester
 SG_ IN_ANA_Val : 0|32@1+ (1,0) [0|4294967295] ""  Tester

BO_ 2147487252 In_Ana_04_Sts: 8 BSG_Master
 SG_ IN_ANA_DIAG : 32|16@1+ (1,0) [0|65535] ""  Tester
 SG_ IN_ANA_Val : 0|32@1+ (1,0) [0|4294967295] ""  Tester

BO_ 2147487253 In_Ana_05_Sts: 8 BSG_Master
 SG_ IN_ANA_DIAG : 32|16@1+ (1,0) [0|65535] ""  Tester
 SG_ IN_ANA_Val : 0|32@1+ (1,0) [0|4294967295] ""  Tester

BO_ 2147487254 In_Ana_06_Sts: 8 BSG_Master
 SG_ IN_ANA_DIAG : 32|16@1+ (1,0) [0|65535] ""  Tester
 SG_ IN_ANA_Val : 0|32@1+ (1,0) [0|4294967295] ""  Tester

BO_ 2147487255 In_Ana_07_Sts: 8 BSG_Master
 SG_ IN_ANA_DIAG : 32|16@1+ (1,0) [0|65535] ""  Tester
 SG_ IN_ANA_Val : 0|32@1+ (1,0) [0|4294967295] ""  Tester

BO_ 2147487256 IN_ANA_08_SEL1_Sts: 8 BSG_Master
 SG_ IN_ANA_DIAG : 32|16@1+ (1,0) [0|65535] ""  Tester
 SG_ IN_ANA_Val : 0|32@1+ (1,0) [0|4294967295] ""  Tester

BO_ 2147487257 IN_ANA_09_SEL1_Sts: 8 BSG_Master
 SG_ IN_ANA_DIAG : 32|16@1+ (1,0) [0|65535] ""  Tester
 SG_ IN_ANA_Val : 0|32@1+ (1,0) [0|4294967295] ""  Tester

BO_ 2147487258 IN_ANA_10_SEL1_Sts: 8 BSG_Master
 SG_ IN_ANA_DIAG : 32|16@1+ (1,0) [0|65535] ""  Tester
 SG_ IN_ANA_Val : 0|32@1+ (1,0) [0|4294967295] ""  Tester

BO_ 2147487259 IN_ANA_11_SEL1_Sts: 8 BSG_Master
 SG_ IN_ANA_DIAG : 32|16@1+ (1,0) [0|65535] ""  Tester
 SG_ IN_ANA_Val : 0|32@1+ (1,0) [0|4294967295] ""  Tester

BO_ 2147487260 In_Ana_12_Sts: 8 BSG_Master
 SG_ IN_ANA_DIAG : 32|16@1+ (1,0) [0|65535] ""  Tester
 SG_ IN_ANA_Val : 0|32@1+ (1,0) [0|4294967295] ""  Tester

BO_ 2147487261 In_Ana_13_Sts: 8 BSG_Master
 SG_ IN_ANA_DIAG : 32|16@1+ (1,0) [0|65535] ""  Tester
 SG_ IN_ANA_Val : 0|32@1+ (1,0) [0|4294967295] ""  Tester

BO_ 2147487262 In_Ana_14_Sts: 8 BSG_Master
 SG_ IN_ANA_DIAG : 32|16@1+ (1,0) [0|65535] ""  Tester
 SG_ IN_ANA_Val : 0|32@1+ (1,0) [0|4294967295] ""  Tester

BO_ 2147487263 In_Ana_15_Sts: 8 BSG_Master
 SG_ IN_ANA_DIAG : 32|16@1+ (1,0) [0|65535] ""  Tester
 SG_ IN_ANA_Val : 0|32@1+ (1,0) [0|4294967295] ""  Tester

BO_ 2147487264 IN_ANA_08_SEL2_Sts: 8 BSG_Master
 SG_ IN_ANA_DIAG : 32|16@1+ (1,0) [0|65535] ""  Tester
 SG_ IN_ANA_Val : 0|32@1+ (1,0) [0|4294967295] ""  Tester

BO_ 2147487265 IN_ANA_09_SEL2_Sts: 8 BSG_Master
 SG_ IN_ANA_DIAG : 32|16@1+ (1,0) [0|65535] ""  Tester
 SG_ IN_ANA_Val : 0|32@1+ (1,0) [0|4294967295] ""  Tester

BO_ 2147487266 IN_ANA_10_SEL2_Sts: 8 BSG_Master
 SG_ IN_ANA_DIAG : 32|16@1+ (1,0) [0|65535] ""  Tester
 SG_ IN_ANA_Val : 0|32@1+ (1,0) [0|4294967295] ""  Tester

BO_ 2147487267 IN_ANA_11_SEL2_Sts: 8 BSG_Master
 SG_ IN_ANA_DIAG : 32|16@1+ (1,0) [0|65535] ""  Tester
 SG_ IN_ANA_Val : 0|32@1+ (1,0) [0|4294967295] ""  Tester

BO_ 2147487488 DateTime_LocalTime_Sts: 8 BSG_Master
 SG_ DateTime_DIAG : 32|16@1+ (1,0) [0|65535] ""  Tester
 SG_ DateTime_LocalTime : 0|32@1+ (1,0) [0|4294967295] ""  Tester

BO_ 2147487489 DateTime_SystemTime_Sts: 8 BSG_Master
 SG_ DateTime_DIAG : 32|16@1+ (1,0) [0|65535] ""  Tester
 SG_ DateTime_SystemTime : 0|32@1+ (1,0) [0|4294967295] ""  Tester

BO_ 2147487490 DateTime_TicksCount_Sts: 8 BSG_Master
 SG_ DateTime_DIAG : 32|16@1+ (1,0) [0|65535] ""  Tester
 SG_ DateTime_TicksCount : 0|32@1+ (1,0) [0|4294967295] ""  Tester

BO_ 2147487491 DateTime_SetTime_Ctrl: 8 Tester
 SG_ DateTime_HourOffset : 0|8@1- (1,0) [-128|127] ""  BSG_Master
 SG_ DateTime_MinuteOffset : 8|8@1- (1,0) [-128|127] ""  BSG_Master
 SG_ DateTime_NewSystemTime : 16|32@1+ (1,0) [0|4294967295] ""  BSG_Master
 SG_ DateTime_SetTime : 48|1@1+ (1,0) [0|1] ""  BSG_Master

BO_ 2147487492 DateTime_SetTime_Sts: 8 BSG_Master
 SG_ DateTime_DIAG : 0|16@1+ (1,0) [0|65535] ""  Tester

BO_ 2147487729 GATEWAY_M1: 8 BSG_Master
 SG_ N1_Gateway : 0|32@1+ (1,0) [0|4294967295] ""  Tester
 SG_ N2_Gateway : 32|32@1+ (1,0) [0|4294967295] ""  Tester

BO_ 2147487730 GATEWAY_M2: 8 BSG_Master
 SG_ N1_Gateway : 0|32@1+ (1,0) [0|4294967295] ""  Tester
 SG_ N2_Gateway : 32|32@1+ (1,0) [0|4294967295] ""  Tester

BO_ 2147487731 GATEWAY_M3: 8 Tester
 SG_ N1_Gateway : 0|32@1+ (1,0) [0|4294967295] ""  BSG_Master
 SG_ N2_Gateway : 32|32@1+ (1,0) [0|4294967295] ""  BSG_Master

BO_ 2147487732 GATEWAY_M4: 8 BSG_Master
 SG_ N1_Gateway : 0|32@1+ (1,0) [0|4294967295] ""  Tester
 SG_ N2_Gateway : 32|32@1+ (1,0) [0|4294967295] ""  Tester

BO_ 2147487733 GATEWAY_M5: 8 BSG_Master
 SG_ N1_Gateway : 0|32@1+ (1,0) [0|4294967295] ""  Tester
 SG_ N2_Gateway : 32|32@1+ (1,0) [0|4294967295] ""  Tester

BO_ 2147487734 GATEWAY_M6: 8 BSG_Master
 SG_ N1_Gateway : 0|32@1+ (1,0) [0|4294967295] ""  Tester
 SG_ N2_Gateway : 32|32@1+ (1,0) [0|4294967295] ""  Tester

BO_ 2147487735 GATEWAY_M7: 8 BSG_Master
 SG_ N1_Gateway : 0|32@1+ (1,0) [0|4294967295] ""  Tester
 SG_ N2_Gateway : 32|32@1+ (1,0) [0|4294967295] ""  Tester

BO_ 2147535873 Out_01_TD_Sts: 4 BSG_Master
 SG_ Out_SENSE_PULSE : 0|16@1+ (1,0) [0|0] ""  Tester
 SG_ Out_SENSE_PULSE_DIAG : 16|16@1+ (1,0) [0|0] ""  Tester

BO_ 2147535876 Out_04_TD_Sts: 4 BSG_Master
 SG_ Out_SENSE_PULSE : 0|16@1+ (1,0) [0|0] ""  Tester
 SG_ Out_SENSE_PULSE_DIAG : 16|16@1+ (1,0) [0|0] ""  Tester

BO_ 2147535878 Out_06_TD_Sts: 4 BSG_Master
 SG_ Out_SENSE_PULSE : 0|16@1+ (1,0) [0|0] ""  Tester
 SG_ Out_SENSE_PULSE_DIAG : 16|16@1+ (1,0) [0|0] ""  Tester

BO_ 2147535879 Out_07_TD_Sts: 4 BSG_Master
 SG_ Out_SENSE_PULSE : 0|16@1+ (1,0) [0|0] ""  Tester
 SG_ Out_SENSE_PULSE_DIAG : 16|16@1+ (1,0) [0|0] ""  Tester

BO_ 2147535880 Out_08_TD_Sts: 4 BSG_Master
 SG_ Out_SENSE_PULSE : 0|16@1+ (1,0) [0|0] ""  Tester
 SG_ Out_SENSE_PULSE_DIAG : 16|16@1+ (1,0) [0|0] ""  Tester

BO_ 2147535884 Out_12_TD_Sts: 4 BSG_Master
 SG_ Out_SENSE_PULSE : 0|16@1+ (1,0) [0|0] ""  Tester
 SG_ Out_SENSE_PULSE_DIAG : 16|16@1+ (1,0) [0|0] ""  Tester

BO_ 2147535885 Out_13_TD_Sts: 4 BSG_Master
 SG_ Out_SENSE_PULSE : 0|16@1+ (1,0) [0|0] ""  Tester
 SG_ Out_SENSE_PULSE_DIAG : 16|16@1+ (1,0) [0|0] ""  Tester

BO_ 2147535886 Out_14_TD_Sts: 4 BSG_Master
 SG_ Out_SENSE_PULSE : 0|16@1+ (1,0) [0|0] ""  Tester
 SG_ Out_SENSE_PULSE_DIAG : 16|16@1+ (1,0) [0|0] ""  Tester

BO_ 2147535887 Out_15_TD_Sts: 4 BSG_Master
 SG_ Out_SENSE_PULSE : 0|16@1+ (1,0) [0|0] ""  Tester
 SG_ Out_SENSE_PULSE_DIAG : 16|16@1+ (1,0) [0|0] ""  Tester

BO_ 2147535892 Out_20_TD_Sts: 4 BSG_Master
 SG_ Out_SENSE_PULSE : 0|16@1+ (1,0) [0|0] ""  Tester
 SG_ Out_SENSE_PULSE_DIAG : 16|16@1+ (1,0) [0|0] ""  Tester

BO_ 2147535893 Out_21_TD_Sts: 4 BSG_Master
 SG_ Out_SENSE_PULSE : 0|16@1+ (1,0) [0|0] ""  Tester
 SG_ Out_SENSE_PULSE_DIAG : 16|16@1+ (1,0) [0|0] ""  Tester

BO_ 2564429808 XCP_REQUEST_IC: 8 Tester
 SG_ N_PDU : 0|64@1+ (1,0) [0|0] ""  BSG_Master

BO_ 2564429809 DIAGNOSTICS_REQUEST_IC: 8 Tester
 SG_ N_PDU : 0|64@1+ (1,0) [0|0] ""  BSG_Master

BO_ 2564432369 DIAGNOSTICS_REQUEST_BSG_Master: 8 Tester
 SG_ N_PDU : 0|64@1+ (1,0) [0|0] ""  BSG_Master

BO_ 2564481521 DIAGNOSTICS_REQUEST_BSG_Exp: 8 Tester
 SG_ N_PDU : 0|64@1+ (1,0) [0|0] ""  BSG_Master

BO_ 2564485143 XCP_RESPONSE_IC: 8 BSG_Master
 SG_ N_PDU : 0|64@1+ (1,0) [0|0] ""  Tester

BO_ 2564485399 DIAGNOSTICS_RESPONSE_IC: 8 BSG_Master
 SG_ N_PDU : 0|64@1+ (1,0) [0|0] ""  Tester

BO_ 2564485409 DIAGNOSTICS_RESPONSE_BSG_Master: 8 BSG_Master
 SG_ N_PDU : 0|64@1+ (1,0) [0|0] ""  Tester

BO_ 2564485601 DIAGNOSTICS_RESPONSE_BSG_Exp: 8 BSG_Master
 SG_ N_PDU : 0|64@1+ (1,0) [0|0] ""  Tester

BO_ 2566834704 DM01_Tester: 22 Tester
 SG_ AmberWarningLampStatus : 2|2@1+ (1,0) [0|3] ""  BSG_Master
 SG_ DTC1 : 16|32@1+ (1,0) [0|4294967295] ""  BSG_Master
 SG_ DTC2 : 48|32@1+ (1,0) [0|4294967295] ""  BSG_Master
 SG_ DTC3 : 80|32@1+ (1,0) [0|4294967295] ""  BSG_Master
 SG_ DTC4 : 112|32@1+ (1,0) [0|4294967295] ""  BSG_Master
 SG_ DTC5 : 144|32@1+ (1,0) [0|4294967295] ""  BSG_Master
 SG_ FlashAmberWarningLamp : 10|2@1+ (1,0) [0|3] ""  BSG_Master
 SG_ FlashMalfuncIndicatorLamp : 14|2@1+ (1,0) [0|3] ""  BSG_Master
 SG_ FlashProtectLamp : 8|2@1+ (1,0) [0|3] ""  BSG_Master
 SG_ FlashRedStopLamp : 12|2@1+ (1,0) [0|3] ""  BSG_Master
 SG_ MalfunctionIndicatorLampStatus : 6|2@1+ (1,0) [0|3] ""  BSG_Master
 SG_ ProtectLampStatus : 0|2@1+ (1,0) [0|3] ""  BSG_Master
 SG_ RedStopLampState : 4|2@1+ (1,0) [0|3] ""  BSG_Master

BO_ 2566834721 DM01_BSG: 22 BSG_Master
 SG_ AmberWarningLampStatus : 2|2@1+ (1,0) [0|3] ""  Tester
 SG_ DTC1 : 16|32@1+ (1,0) [0|4294967295] ""  Tester
 SG_ DTC2 : 48|32@1+ (1,0) [0|4294967295] ""  Tester
 SG_ DTC3 : 80|32@1+ (1,0) [0|4294967295] ""  Tester
 SG_ DTC4 : 112|32@1+ (1,0) [0|4294967295] ""  Tester
 SG_ DTC5 : 144|32@1+ (1,0) [0|4294967295] ""  Tester
 SG_ FlashAmberWarningLamp : 10|2@1+ (1,0) [0|3] ""  Tester
 SG_ FlashMalfuncIndicatorLamp : 14|2@1+ (1,0) [0|3] ""  Tester
 SG_ FlashProtectLamp : 8|2@1+ (1,0) [0|3] ""  Tester
 SG_ FlashRedStopLamp : 12|2@1+ (1,0) [0|3] ""  Tester
 SG_ MalfunctionIndicatorLampStatus : 6|2@1+ (1,0) [0|3] ""  Tester
 SG_ ProtectLampStatus : 0|2@1+ (1,0) [0|3] ""  Tester
 SG_ RedStopLampState : 4|2@1+ (1,0) [0|3] ""  Tester

CM_ BO_ 2147486465 "Control of digital outputs";
CM_ BO_ 2147486466 "Control of digital outputs (PWM)";
CM_ BO_ 2147486721 "Status of Output";
CM_ BO_ 2147486722 "Status of Output";
CM_ BO_ 2147486723 "Status of Output";
CM_ BO_ 2147486724 "Status of Output";
CM_ BO_ 2147486725 "Status of Output";
CM_ BO_ 2147486726 "Status of Output";
CM_ BO_ 2147486727 "Status of Output";
CM_ BO_ 2147486728 "Status of Output";
CM_ BO_ 2147486729 "Status of Output";
CM_ BO_ 2147486730 "Status of Output";
CM_ BO_ 2147486731 "Status of Output";
CM_ BO_ 2147486732 "Status of Output";
CM_ BO_ 2147486733 "Status of Output";
CM_ BO_ 2147486734 "Status of Output";
CM_ BO_ 2147486735 "Status of Output";
CM_ BO_ 2147486736 "Status of Output";
CM_ BO_ 2147486737 "Status of Output";
CM_ BO_ 2147486738 "Status of Output";
CM_ BO_ 2147486739 "Status of Output";
CM_ BO_ 2147486740 "Status of Output";
CM_ BO_ 2147486741 "Status of Output";
CM_ BO_ 2147486742 "Status of Output";
CM_ BO_ 2147486743 "Status of Output";
CM_ BO_ 2147486744 "Status of Output";
CM_ BO_ 2147486745 "Status of Output";
CM_ BO_ 2147486746 "Status of Output";
CM_ BO_ 2147486747 "Status of Output";
CM_ BO_ 2147486750 "Status of Output";
CM_ BO_ 2147486751 "Status of Output";
CM_ BO_ 2147486752 "Status of Output";
CM_ BO_ 2147486977 "Status of Output";
CM_ BO_ 2147486978 "Status of Output";
CM_ BO_ 2147486979 "Status of Output";
CM_ BO_ 2147486980 "Status of Output";
CM_ BO_ 2147486981 "Status of Output";
CM_ BO_ 2147486982 "Status of Output";
CM_ BO_ 2147486983 "Status of Output";
CM_ BO_ 2147486984 "Status of Output";
CM_ BO_ 2147486985 "Status of Output";
CM_ BO_ 2147486986 "Status of Output";
CM_ BO_ 2147486987 "Status of Output";
CM_ BO_ 2147486988 "Status of Output";
CM_ BO_ 2147486989 "Status of Output";
CM_ BO_ 2147486990 "Status of Output";
CM_ BO_ 2147486991 "Status of Output";
CM_ BO_ 2147486992 "Status of Output";
CM_ BO_ 2147486993 "Status of Output";
CM_ BO_ 2147486994 "Status of Output";
CM_ BO_ 2147486995 "Status of Output";
CM_ BO_ 2147486996 "Status of Output";
CM_ BO_ 2147486997 "Status of Output";
CM_ BO_ 2147486998 "Status of Output";
CM_ BO_ 2147486999 "Status of Output";
CM_ BO_ 2147487000 "Status of Output";
CM_ BO_ 2147487001 "Status of Output";
CM_ BO_ 2147487002 "Status of Output";
CM_ BO_ 2147487003 "Status of Output";
CM_ BO_ 2147487004 "Status of Output";
CM_ BO_ 2147487005 "Status of Output";
CM_ BO_ 2147487006 "Status of Output";
CM_ BO_ 2147487007 "Status of Output";
CM_ BO_ 2147487008 "Status of Output";
CM_ BO_ 2147487009 "Status of Output";
CM_ BO_ 2147487010 "Status of Output";
CM_ BO_ 2147487011 "Status of Output";
CM_ BO_ 2147487012 "Status of Output";
CM_ BO_ 2147487013 "Status of Output";
CM_ BO_ 2147487014 "Status of Output";
CM_ BO_ 2147487015 "Status of Output";
CM_ BO_ 2147487016 "Status of Output";
CM_ BO_ 2147487017 "Status of Output";
CM_ BO_ 2147487018 "Status of Output";
CM_ BO_ 2147487019 "Status of Output";
CM_ BO_ 2147487020 "Status of Output";
CM_ BO_ 2147487021 "Status of Output";
CM_ BO_ 2147487022 "Status of Output";
CM_ BO_ 2147487024 "Status of Output";
CM_ BO_ 2147487025 "Status of Output";
CM_ BO_ 2147487026 "Status of Output";
CM_ BO_ 2147487232 "Status of Main Power";
CM_ BO_ 2147487233 "Status of Power Group";
CM_ BO_ 2147487234 "Status of Power Group";
CM_ BO_ 2147487235 "Status of Power Group";
CM_ BO_ 2147487236 "Status of Power Group";
CM_ BO_ 2147487237 "Status of Power Group";
CM_ BO_ 2147487239 "Status of Power Group";
CM_ BO_ 2147487247 "Status of Output";
CM_ BO_ 2147487248 "Status of Output";
CM_ BO_ 2147487249 "Status of Output";
CM_ BO_ 2147487250 "Status of Output";
CM_ BO_ 2147487251 "Status of Output";
CM_ BO_ 2147487252 "Status of Output";
CM_ BO_ 2147487253 "Status of Output";
CM_ BO_ 2147487254 "Status of Output";
CM_ BO_ 2147487255 "Status of Output";
CM_ BO_ 2147487256 "Status of Output";
CM_ BO_ 2147487257 "Status of Output";
CM_ BO_ 2147487258 "Status of Output";
CM_ BO_ 2147487259 "Status of Output";
CM_ BO_ 2147487260 "Status of Output";
CM_ BO_ 2147487261 "Status of Output";
CM_ BO_ 2147487262 "Status of Output";
CM_ BO_ 2147487263 "Status of Output";
CM_ BO_ 2147487264 "Status of Output";
CM_ BO_ 2147487265 "Status of Output";
CM_ BO_ 2147487266 "Status of Output";
CM_ BO_ 2147487267 "Status of Output";
CM_ BO_ 2147487488 "Status of Output";
CM_ BO_ 2147487489 "Status of Output";
CM_ BO_ 2147487490 "Status of Output";
CM_ BO_ 2147487491 "Status of Output";
CM_ BO_ 2147487492 "Status of Output";
CM_ BO_ 2147535873 "Status of Output";
CM_ BO_ 2147535876 "Status of Output";
CM_ BO_ 2147535878 "Status of Output";
CM_ BO_ 2147535879 "Status of Output";
CM_ BO_ 2147535880 "Status of Output";
CM_ BO_ 2147535884 "Status of Output";
CM_ BO_ 2147535885 "Status of Output";
CM_ BO_ 2147535886 "Status of Output";
CM_ BO_ 2147535887 "Status of Output";
CM_ BO_ 2147535892 "Status of Output";
CM_ BO_ 2147535893 "Status of Output";
CM_ BO_ 2564429808 "Diagnostics Request";
CM_ BO_ 2564429809 "Diagnostics Request";
CM_ BO_ 2564432369 "Diagnostics Request";
CM_ BO_ 2564481521 "Diagnostics Request";
CM_ BO_ 2564485143 "Diagnostics Response";
CM_ BO_ 2564485399 "Diagnostics Response";
CM_ BO_ 2564485409 "Diagnostics Response";
CM_ BO_ 2564485601 "Diagnostics Response";
CM_ BO_ 2566834704 "Active Diagnostic Trouble Codes";
CM_ SG_ 2566834704 AmberWarningLampStatus "This lamp is used to relay trouble code information that is reporting a problem with the vehicle system but the vehicle need not be immediately stopped.

00     Lamp Off
01     Lamp On
10     Reserved
11     Not available";
CM_ SG_ 2566834704 DTC1 "Diagnostic Trouble Code";
CM_ SG_ 2566834704 DTC2 "Diagnostic Trouble Code";
CM_ SG_ 2566834704 DTC3 "Diagnostic Trouble Code";
CM_ SG_ 2566834704 DTC4 "Diagnostic Trouble Code";
CM_ SG_ 2566834704 DTC5 "Diagnostic Trouble Code";
CM_ SG_ 2566834704 FlashAmberWarningLamp "This parameter provides the capability to flash the AWL

00 - Slow Flash (1 Hz, 50 % duty cycle)
01 - Fast Flash (2 Hz or faster, 50% duty cycle)
10 - Reserved
11 - Unavailable / Do Not Flash";
CM_ SG_ 2566834704 FlashMalfuncIndicatorLamp "This parameter provides the capability to flash the MIL
00 - Slow Flash (1 Hz, 50 % duty cycle)
01 - Fast Flash (2 Hz or faster, 50% duty cycle)
10 - Class C DTC
11 - Unavailable / Do Not Flash
Note:  State 10 is for WWH OBD discriminatory ...";
CM_ SG_ 2566834704 FlashProtectLamp "This parameter provides the capability to flash the engine protect lamp


00 - Slow Flash (1 Hz, 50 % duty cycle)
01 - Fast Flash (2 Hz or faster, 50% duty cycle)
10 - Reserved
11 - Unavailable / Do Not Flash";
CM_ SG_ 2566834704 FlashRedStopLamp "This parameter provides the capability to flash the RSL


00 - Slow Flash (1 Hz, 50 % duty cycle)
01 - Fast Flash (2 Hz or faster, 50% duty cycle)
10 - Reserved
11 - Unavailable / Do Not Flash";
CM_ SG_ 2566834704 MalfunctionIndicatorLampStatus "A lamp used to relay only emissions-related trouble code information. This lamp is only illuminated when there is an emission-related trouble code active.
00     Lamp Off
01     Lamp On
10     Short MIL for WWH OBD
11     Not available
Note ...";
CM_ SG_ 2566834704 ProtectLampStatus "This lamp is used to relay trouble code information that is reporting a problem with a vehicle system that is most probably not electronic subsystem related. For instance, engine coolant temperature is exceeding its prescribed temperature range.
00 ...";
CM_ SG_ 2566834704 RedStopLampState "This lamp is used to relay trouble code information that is of a severe enough condition that it warrants stopping the vehicle.

00     Lamp Off
01     Lamp On
10     Reserved
11     Not available";
CM_ BO_ 2566834721 "Active Diagnostic Trouble Codes";
CM_ SG_ 2566834721 AmberWarningLampStatus "This lamp is used to relay trouble code information that is reporting a problem with the vehicle system but the vehicle need not be immediately stopped.

00     Lamp Off
01     Lamp On
10     Reserved
11     Not available";
CM_ SG_ 2566834721 DTC1 "Diagnostic Trouble Code";
CM_ SG_ 2566834721 DTC2 "Diagnostic Trouble Code";
CM_ SG_ 2566834721 DTC3 "Diagnostic Trouble Code";
CM_ SG_ 2566834721 DTC4 "Diagnostic Trouble Code";
CM_ SG_ 2566834721 DTC5 "Diagnostic Trouble Code";
CM_ SG_ 2566834721 FlashAmberWarningLamp "This parameter provides the capability to flash the AWL

00 - Slow Flash (1 Hz, 50 % duty cycle)
01 - Fast Flash (2 Hz or faster, 50% duty cycle)
10 - Reserved
11 - Unavailable / Do Not Flash";
CM_ SG_ 2566834721 FlashMalfuncIndicatorLamp "This parameter provides the capability to flash the MIL
00 - Slow Flash (1 Hz, 50 % duty cycle)
01 - Fast Flash (2 Hz or faster, 50% duty cycle)
10 - Class C DTC
11 - Unavailable / Do Not Flash
Note:  State 10 is for WWH OBD discriminatory ...";
CM_ SG_ 2566834721 FlashProtectLamp "This parameter provides the capability to flash the engine protect lamp


00 - Slow Flash (1 Hz, 50 % duty cycle)
01 - Fast Flash (2 Hz or faster, 50% duty cycle)
10 - Reserved
11 - Unavailable / Do Not Flash";
CM_ SG_ 2566834721 FlashRedStopLamp "This parameter provides the capability to flash the RSL


00 - Slow Flash (1 Hz, 50 % duty cycle)
01 - Fast Flash (2 Hz or faster, 50% duty cycle)
10 - Reserved
11 - Unavailable / Do Not Flash";
CM_ SG_ 2566834721 MalfunctionIndicatorLampStatus "A lamp used to relay only emissions-related trouble code information. This lamp is only illuminated when there is an emission-related trouble code active.
00     Lamp Off
01     Lamp On
10     Short MIL for WWH OBD
11     Not available
Note ...";
CM_ SG_ 2566834721 ProtectLampStatus "This lamp is used to relay trouble code information that is reporting a problem with a vehicle system that is most probably not electronic subsystem related. For instance, engine coolant temperature is exceeding its prescribed temperature range.
00 ...";
CM_ SG_ 2566834721 RedStopLampState "This lamp is used to relay trouble code information that is of a severe enough condition that it warrants stopping the vehicle.

00     Lamp Off
01     Lamp On
10     Reserved
11     Not available";
BA_DEF_  "BusType" STRING ;
BA_DEF_  "DBName" STRING ;
BA_DEF_  "NmBaseAddress" HEX 1024 1087;
BA_DEF_  "ProtocolType" STRING ;
BA_DEF_ BO_  "GenMsgCycleTime" INT 0 0;
BA_DEF_ BO_  "GenMsgCycleTimeFast" INT 2 50000;
BA_DEF_ BO_  "GenMsgILSupport" ENUM  "No","Yes";
BA_DEF_ BO_  "GenMsgSendType" ENUM  "Cyclic","not_used","not_used","not_used","not_used","Cyclic","not_used","IfActive","NoMsgSendType";
BA_DEF_ BO_  "VFrameFormat" ENUM  "StandardCAN","ExtendedCAN","reserved","J1939PG";
BA_DEF_ BU_  "ILUsed" ENUM  "No","Yes";
BA_DEF_ BU_  "NmStationAddress" HEX 0 0;
BA_DEF_ BU_  "NodeLayerModules" STRING ;
BA_DEF_ SG_  "GenSigSendType" ENUM  "Cyclic","OnWrite","OnWriteWithRepetition","OnChange","OnChangeWithRepetition","IfActive","IfActiveWithRepetition","NoSigSendType";
BA_DEF_ SG_  "NWM-WakeupAllowed" ENUM  "No","Yes";
BA_DEF_ SG_  "SPN" INT 0 524287;
BA_DEF_ SG_  "SigType" ENUM  "Default","Range","RangeSigned","ASCII","Discrete","Control","ReferencePGN","DTC","StringDelimiter","StringLength","StringLengthControl","MessageCounter","MessageChecksum";
BA_DEF_DEF_  "BusType" "CAN";
BA_DEF_DEF_  "DBName" "";
BA_DEF_DEF_  "NmBaseAddress" 1024;
BA_DEF_DEF_  "ProtocolType" "J1939";
BA_DEF_DEF_  "GenMsgCycleTime" 0;
BA_DEF_DEF_  "GenMsgCycleTimeFast" 100;
BA_DEF_DEF_  "GenMsgILSupport" "Yes";
BA_DEF_DEF_  "GenMsgSendType" "NoMsgSendType";
BA_DEF_DEF_  "VFrameFormat" "";
BA_DEF_DEF_  "ILUsed" "Yes";
BA_DEF_DEF_  "NmStationAddress" 0;
BA_DEF_DEF_  "NodeLayerModules" "";
BA_DEF_DEF_  "GenSigSendType" "Cyclic";
BA_DEF_DEF_  "NWM-WakeupAllowed" "";
BA_DEF_DEF_  "SPN" 0;
BA_DEF_DEF_  "SigType" "Default";
BA_ "DBName" "P_CAN3";
BA_ "NodeLayerModules" BU_ BSG_Master "CANoeILNLVector.dll,J1939_IL.DLL, osek_tp.dll";
BA_ "NmStationAddress" BU_ BSG_Master 33;
BA_ "NodeLayerModules" BU_ Tester "CANoeILNLVector.dll,J1939_IL.DLL";
BA_ "NmStationAddress" BU_ Tester 16;
BA_ "VFrameFormat" BO_ 2147484928 1;
BA_ "VFrameFormat" BO_ 2147484929 1;
BA_ "VFrameFormat" BO_ 2147484930 1;
BA_ "VFrameFormat" BO_ 2147484931 1;
BA_ "VFrameFormat" BO_ 2147484932 1;
BA_ "VFrameFormat" BO_ 2147485184 1;
BA_ "VFrameFormat" BO_ 2147486465 1;
BA_ "GenMsgSendType" BO_ 2147486465 0;
BA_ "GenMsgCycleTime" BO_ 2147486465 100;
BA_ "VFrameFormat" BO_ 2147486466 1;
BA_ "GenMsgSendType" BO_ 2147486466 0;
BA_ "GenMsgCycleTime" BO_ 2147486466 100;
BA_ "VFrameFormat" BO_ 2147486467 1;
BA_ "GenMsgSendType" BO_ 2147486467 0;
BA_ "GenMsgCycleTime" BO_ 2147486467 100;
BA_ "VFrameFormat" BO_ 2147486721 1;
BA_ "GenMsgSendType" BO_ 2147486721 0;
BA_ "GenMsgCycleTime" BO_ 2147486721 100;
BA_ "VFrameFormat" BO_ 2147486722 1;
BA_ "GenMsgSendType" BO_ 2147486722 0;
BA_ "GenMsgCycleTime" BO_ 2147486722 100;
BA_ "VFrameFormat" BO_ 2147486723 1;
BA_ "GenMsgSendType" BO_ 2147486723 0;
BA_ "GenMsgCycleTime" BO_ 2147486723 100;
BA_ "VFrameFormat" BO_ 2147486724 1;
BA_ "GenMsgSendType" BO_ 2147486724 0;
BA_ "GenMsgCycleTime" BO_ 2147486724 100;
BA_ "VFrameFormat" BO_ 2147486725 1;
BA_ "GenMsgSendType" BO_ 2147486725 0;
BA_ "GenMsgCycleTime" BO_ 2147486725 100;
BA_ "VFrameFormat" BO_ 2147486726 1;
BA_ "GenMsgSendType" BO_ 2147486726 0;
BA_ "GenMsgCycleTime" BO_ 2147486726 100;
BA_ "VFrameFormat" BO_ 2147486727 1;
BA_ "GenMsgSendType" BO_ 2147486727 0;
BA_ "GenMsgCycleTime" BO_ 2147486727 100;
BA_ "VFrameFormat" BO_ 2147486728 1;
BA_ "GenMsgSendType" BO_ 2147486728 0;
BA_ "GenMsgCycleTime" BO_ 2147486728 100;
BA_ "VFrameFormat" BO_ 2147486729 1;
BA_ "GenMsgSendType" BO_ 2147486729 0;
BA_ "GenMsgCycleTime" BO_ 2147486729 100;
BA_ "VFrameFormat" BO_ 2147486730 1;
BA_ "GenMsgSendType" BO_ 2147486730 0;
BA_ "GenMsgCycleTime" BO_ 2147486730 100;
BA_ "VFrameFormat" BO_ 2147486731 1;
BA_ "GenMsgSendType" BO_ 2147486731 0;
BA_ "GenMsgCycleTime" BO_ 2147486731 100;
BA_ "VFrameFormat" BO_ 2147486732 1;
BA_ "GenMsgSendType" BO_ 2147486732 0;
BA_ "GenMsgCycleTime" BO_ 2147486732 100;
BA_ "VFrameFormat" BO_ 2147486733 1;
BA_ "GenMsgSendType" BO_ 2147486733 0;
BA_ "GenMsgCycleTime" BO_ 2147486733 100;
BA_ "VFrameFormat" BO_ 2147486734 1;
BA_ "GenMsgSendType" BO_ 2147486734 0;
BA_ "GenMsgCycleTime" BO_ 2147486734 100;
BA_ "VFrameFormat" BO_ 2147486735 1;
BA_ "GenMsgSendType" BO_ 2147486735 0;
BA_ "GenMsgCycleTime" BO_ 2147486735 100;
BA_ "VFrameFormat" BO_ 2147486736 1;
BA_ "GenMsgSendType" BO_ 2147486736 0;
BA_ "GenMsgCycleTime" BO_ 2147486736 100;
BA_ "VFrameFormat" BO_ 2147486737 1;
BA_ "GenMsgSendType" BO_ 2147486737 0;
BA_ "GenMsgCycleTime" BO_ 2147486737 100;
BA_ "VFrameFormat" BO_ 2147486738 1;
BA_ "GenMsgSendType" BO_ 2147486738 0;
BA_ "GenMsgCycleTime" BO_ 2147486738 100;
BA_ "VFrameFormat" BO_ 2147486739 1;
BA_ "GenMsgSendType" BO_ 2147486739 0;
BA_ "GenMsgCycleTime" BO_ 2147486739 100;
BA_ "VFrameFormat" BO_ 2147486740 1;
BA_ "GenMsgSendType" BO_ 2147486740 0;
BA_ "GenMsgCycleTime" BO_ 2147486740 100;
BA_ "VFrameFormat" BO_ 2147486741 1;
BA_ "GenMsgSendType" BO_ 2147486741 0;
BA_ "GenMsgCycleTime" BO_ 2147486741 100;
BA_ "VFrameFormat" BO_ 2147486742 1;
BA_ "GenMsgSendType" BO_ 2147486742 0;
BA_ "GenMsgCycleTime" BO_ 2147486742 100;
BA_ "VFrameFormat" BO_ 2147486743 1;
BA_ "GenMsgSendType" BO_ 2147486743 0;
BA_ "GenMsgCycleTime" BO_ 2147486743 100;
BA_ "VFrameFormat" BO_ 2147486744 1;
BA_ "GenMsgSendType" BO_ 2147486744 0;
BA_ "GenMsgCycleTime" BO_ 2147486744 100;
BA_ "VFrameFormat" BO_ 2147486745 1;
BA_ "GenMsgSendType" BO_ 2147486745 0;
BA_ "GenMsgCycleTime" BO_ 2147486745 100;
BA_ "VFrameFormat" BO_ 2147486746 1;
BA_ "GenMsgSendType" BO_ 2147486746 0;
BA_ "GenMsgCycleTime" BO_ 2147486746 100;
BA_ "VFrameFormat" BO_ 2147486747 1;
BA_ "GenMsgSendType" BO_ 2147486747 0;
BA_ "GenMsgCycleTime" BO_ 2147486747 100;
BA_ "VFrameFormat" BO_ 2147486748 1;
BA_ "GenMsgSendType" BO_ 2147486748 0;
BA_ "GenMsgCycleTime" BO_ 2147486748 500;
BA_ "VFrameFormat" BO_ 2147486749 1;
BA_ "GenMsgCycleTime" BO_ 2147486749 100;
BA_ "VFrameFormat" BO_ 2147486750 1;
BA_ "GenMsgSendType" BO_ 2147486750 0;
BA_ "GenMsgCycleTimeFast" BO_ 2147486750 200;
BA_ "GenMsgCycleTime" BO_ 2147486750 200;
BA_ "VFrameFormat" BO_ 2147486751 1;
BA_ "GenMsgSendType" BO_ 2147486751 0;
BA_ "GenMsgCycleTimeFast" BO_ 2147486751 200;
BA_ "GenMsgCycleTime" BO_ 2147486751 200;
BA_ "VFrameFormat" BO_ 2147486752 1;
BA_ "GenMsgSendType" BO_ 2147486752 0;
BA_ "GenMsgCycleTimeFast" BO_ 2147486752 200;
BA_ "GenMsgCycleTime" BO_ 2147486752 200;
BA_ "VFrameFormat" BO_ 2147486977 1;
BA_ "GenMsgSendType" BO_ 2147486977 0;
BA_ "GenMsgCycleTime" BO_ 2147486977 100;
BA_ "VFrameFormat" BO_ 2147486978 1;
BA_ "GenMsgSendType" BO_ 2147486978 0;
BA_ "GenMsgCycleTime" BO_ 2147486978 100;
BA_ "VFrameFormat" BO_ 2147486979 1;
BA_ "GenMsgSendType" BO_ 2147486979 0;
BA_ "GenMsgCycleTime" BO_ 2147486979 100;
BA_ "VFrameFormat" BO_ 2147486980 1;
BA_ "GenMsgSendType" BO_ 2147486980 0;
BA_ "GenMsgCycleTime" BO_ 2147486980 100;
BA_ "VFrameFormat" BO_ 2147486981 1;
BA_ "GenMsgSendType" BO_ 2147486981 0;
BA_ "GenMsgCycleTime" BO_ 2147486981 100;
BA_ "VFrameFormat" BO_ 2147486982 1;
BA_ "GenMsgSendType" BO_ 2147486982 0;
BA_ "GenMsgCycleTime" BO_ 2147486982 100;
BA_ "VFrameFormat" BO_ 2147486983 1;
BA_ "GenMsgSendType" BO_ 2147486983 0;
BA_ "GenMsgCycleTime" BO_ 2147486983 100;
BA_ "VFrameFormat" BO_ 2147486984 1;
BA_ "GenMsgSendType" BO_ 2147486984 0;
BA_ "GenMsgCycleTime" BO_ 2147486984 100;
BA_ "VFrameFormat" BO_ 2147486985 1;
BA_ "GenMsgSendType" BO_ 2147486985 0;
BA_ "GenMsgCycleTime" BO_ 2147486985 100;
BA_ "VFrameFormat" BO_ 2147486986 1;
BA_ "GenMsgSendType" BO_ 2147486986 0;
BA_ "GenMsgCycleTime" BO_ 2147486986 100;
BA_ "VFrameFormat" BO_ 2147486987 1;
BA_ "GenMsgSendType" BO_ 2147486987 0;
BA_ "GenMsgCycleTime" BO_ 2147486987 100;
BA_ "VFrameFormat" BO_ 2147486988 1;
BA_ "GenMsgSendType" BO_ 2147486988 0;
BA_ "GenMsgCycleTime" BO_ 2147486988 100;
BA_ "VFrameFormat" BO_ 2147486989 1;
BA_ "GenMsgSendType" BO_ 2147486989 0;
BA_ "GenMsgCycleTime" BO_ 2147486989 100;
BA_ "VFrameFormat" BO_ 2147486990 1;
BA_ "GenMsgSendType" BO_ 2147486990 0;
BA_ "GenMsgCycleTime" BO_ 2147486990 100;
BA_ "VFrameFormat" BO_ 2147486991 1;
BA_ "GenMsgSendType" BO_ 2147486991 0;
BA_ "GenMsgCycleTime" BO_ 2147486991 100;
BA_ "VFrameFormat" BO_ 2147486992 1;
BA_ "GenMsgSendType" BO_ 2147486992 0;
BA_ "GenMsgCycleTime" BO_ 2147486992 100;
BA_ "VFrameFormat" BO_ 2147486993 1;
BA_ "GenMsgSendType" BO_ 2147486993 0;
BA_ "GenMsgCycleTime" BO_ 2147486993 100;
BA_ "VFrameFormat" BO_ 2147486994 1;
BA_ "GenMsgSendType" BO_ 2147486994 0;
BA_ "GenMsgCycleTime" BO_ 2147486994 100;
BA_ "VFrameFormat" BO_ 2147486995 1;
BA_ "GenMsgSendType" BO_ 2147486995 0;
BA_ "GenMsgCycleTime" BO_ 2147486995 100;
BA_ "VFrameFormat" BO_ 2147486996 1;
BA_ "GenMsgSendType" BO_ 2147486996 0;
BA_ "GenMsgCycleTime" BO_ 2147486996 100;
BA_ "VFrameFormat" BO_ 2147486997 1;
BA_ "GenMsgSendType" BO_ 2147486997 0;
BA_ "GenMsgCycleTime" BO_ 2147486997 100;
BA_ "VFrameFormat" BO_ 2147486998 1;
BA_ "GenMsgSendType" BO_ 2147486998 0;
BA_ "GenMsgCycleTime" BO_ 2147486998 100;
BA_ "VFrameFormat" BO_ 2147486999 1;
BA_ "GenMsgSendType" BO_ 2147486999 0;
BA_ "GenMsgCycleTime" BO_ 2147486999 100;
BA_ "VFrameFormat" BO_ 2147487000 1;
BA_ "GenMsgSendType" BO_ 2147487000 0;
BA_ "GenMsgCycleTime" BO_ 2147487000 100;
BA_ "VFrameFormat" BO_ 2147487001 1;
BA_ "GenMsgSendType" BO_ 2147487001 0;
BA_ "GenMsgCycleTime" BO_ 2147487001 100;
BA_ "VFrameFormat" BO_ 2147487002 1;
BA_ "GenMsgSendType" BO_ 2147487002 0;
BA_ "GenMsgCycleTime" BO_ 2147487002 100;
BA_ "VFrameFormat" BO_ 2147487003 1;
BA_ "GenMsgSendType" BO_ 2147487003 0;
BA_ "GenMsgCycleTime" BO_ 2147487003 100;
BA_ "VFrameFormat" BO_ 2147487004 1;
BA_ "GenMsgSendType" BO_ 2147487004 0;
BA_ "GenMsgCycleTime" BO_ 2147487004 100;
BA_ "VFrameFormat" BO_ 2147487005 1;
BA_ "GenMsgSendType" BO_ 2147487005 0;
BA_ "GenMsgCycleTime" BO_ 2147487005 100;
BA_ "VFrameFormat" BO_ 2147487006 1;
BA_ "GenMsgSendType" BO_ 2147487006 0;
BA_ "GenMsgCycleTime" BO_ 2147487006 100;
BA_ "VFrameFormat" BO_ 2147487007 1;
BA_ "GenMsgSendType" BO_ 2147487007 0;
BA_ "GenMsgCycleTime" BO_ 2147487007 100;
BA_ "VFrameFormat" BO_ 2147487008 1;
BA_ "GenMsgSendType" BO_ 2147487008 0;
BA_ "GenMsgCycleTime" BO_ 2147487008 100;
BA_ "VFrameFormat" BO_ 2147487009 1;
BA_ "GenMsgSendType" BO_ 2147487009 0;
BA_ "GenMsgCycleTime" BO_ 2147487009 100;
BA_ "VFrameFormat" BO_ 2147487010 1;
BA_ "GenMsgSendType" BO_ 2147487010 0;
BA_ "GenMsgCycleTime" BO_ 2147487010 100;
BA_ "VFrameFormat" BO_ 2147487011 1;
BA_ "GenMsgSendType" BO_ 2147487011 0;
BA_ "GenMsgCycleTime" BO_ 2147487011 100;
BA_ "VFrameFormat" BO_ 2147487012 1;
BA_ "GenMsgSendType" BO_ 2147487012 0;
BA_ "GenMsgCycleTime" BO_ 2147487012 100;
BA_ "VFrameFormat" BO_ 2147487013 1;
BA_ "GenMsgSendType" BO_ 2147487013 0;
BA_ "GenMsgCycleTime" BO_ 2147487013 100;
BA_ "VFrameFormat" BO_ 2147487014 1;
BA_ "GenMsgSendType" BO_ 2147487014 0;
BA_ "GenMsgCycleTime" BO_ 2147487014 100;
BA_ "VFrameFormat" BO_ 2147487015 1;
BA_ "GenMsgSendType" BO_ 2147487015 0;
BA_ "GenMsgCycleTime" BO_ 2147487015 100;
BA_ "VFrameFormat" BO_ 2147487016 1;
BA_ "GenMsgSendType" BO_ 2147487016 0;
BA_ "GenMsgCycleTime" BO_ 2147487016 100;
BA_ "VFrameFormat" BO_ 2147487017 1;
BA_ "GenMsgSendType" BO_ 2147487017 0;
BA_ "GenMsgCycleTime" BO_ 2147487017 100;
BA_ "VFrameFormat" BO_ 2147487018 1;
BA_ "GenMsgSendType" BO_ 2147487018 0;
BA_ "GenMsgCycleTime" BO_ 2147487018 100;
BA_ "VFrameFormat" BO_ 2147487019 1;
BA_ "GenMsgSendType" BO_ 2147487019 0;
BA_ "GenMsgCycleTime" BO_ 2147487019 100;
BA_ "VFrameFormat" BO_ 2147487020 1;
BA_ "GenMsgSendType" BO_ 2147487020 0;
BA_ "GenMsgCycleTime" BO_ 2147487020 100;
BA_ "VFrameFormat" BO_ 2147487021 1;
BA_ "GenMsgSendType" BO_ 2147487021 0;
BA_ "GenMsgCycleTime" BO_ 2147487021 100;
BA_ "VFrameFormat" BO_ 2147487022 1;
BA_ "GenMsgSendType" BO_ 2147487022 0;
BA_ "GenMsgCycleTime" BO_ 2147487022 100;
BA_ "VFrameFormat" BO_ 2147487024 1;
BA_ "GenMsgSendType" BO_ 2147487024 0;
BA_ "GenMsgCycleTime" BO_ 2147487024 100;
BA_ "VFrameFormat" BO_ 2147487025 1;
BA_ "GenMsgSendType" BO_ 2147487025 0;
BA_ "GenMsgCycleTime" BO_ 2147487025 100;
BA_ "VFrameFormat" BO_ 2147487026 1;
BA_ "GenMsgSendType" BO_ 2147487026 0;
BA_ "GenMsgCycleTime" BO_ 2147487026 100;
BA_ "VFrameFormat" BO_ 2147487232 1;
BA_ "GenMsgSendType" BO_ 2147487232 0;
BA_ "GenMsgCycleTimeFast" BO_ 2147487232 200;
BA_ "GenMsgCycleTime" BO_ 2147487232 200;
BA_ "VFrameFormat" BO_ 2147487233 1;
BA_ "GenMsgSendType" BO_ 2147487233 0;
BA_ "GenMsgCycleTimeFast" BO_ 2147487233 200;
BA_ "GenMsgCycleTime" BO_ 2147487233 200;
BA_ "VFrameFormat" BO_ 2147487234 1;
BA_ "GenMsgSendType" BO_ 2147487234 0;
BA_ "GenMsgCycleTimeFast" BO_ 2147487234 200;
BA_ "GenMsgCycleTime" BO_ 2147487234 200;
BA_ "VFrameFormat" BO_ 2147487235 1;
BA_ "GenMsgSendType" BO_ 2147487235 0;
BA_ "GenMsgCycleTimeFast" BO_ 2147487235 200;
BA_ "GenMsgCycleTime" BO_ 2147487235 200;
BA_ "VFrameFormat" BO_ 2147487236 1;
BA_ "GenMsgSendType" BO_ 2147487236 0;
BA_ "GenMsgCycleTimeFast" BO_ 2147487236 200;
BA_ "GenMsgCycleTime" BO_ 2147487236 200;
BA_ "VFrameFormat" BO_ 2147487237 1;
BA_ "GenMsgSendType" BO_ 2147487237 0;
BA_ "GenMsgCycleTimeFast" BO_ 2147487237 200;
BA_ "GenMsgCycleTime" BO_ 2147487237 200;
BA_ "VFrameFormat" BO_ 2147487239 1;
BA_ "GenMsgSendType" BO_ 2147487239 0;
BA_ "GenMsgCycleTimeFast" BO_ 2147487239 200;
BA_ "GenMsgCycleTime" BO_ 2147487239 200;
BA_ "VFrameFormat" BO_ 2147487247 1;
BA_ "GenMsgSendType" BO_ 2147487247 0;
BA_ "GenMsgCycleTimeFast" BO_ 2147487247 200;
BA_ "GenMsgCycleTime" BO_ 2147487247 200;
BA_ "VFrameFormat" BO_ 2147487248 1;
BA_ "GenMsgSendType" BO_ 2147487248 0;
BA_ "GenMsgCycleTimeFast" BO_ 2147487248 500;
BA_ "GenMsgCycleTime" BO_ 2147487248 500;
BA_ "VFrameFormat" BO_ 2147487249 1;
BA_ "GenMsgSendType" BO_ 2147487249 0;
BA_ "GenMsgCycleTimeFast" BO_ 2147487249 200;
BA_ "GenMsgCycleTime" BO_ 2147487249 200;
BA_ "VFrameFormat" BO_ 2147487250 1;
BA_ "GenMsgSendType" BO_ 2147487250 0;
BA_ "GenMsgCycleTimeFast" BO_ 2147487250 200;
BA_ "GenMsgCycleTime" BO_ 2147487250 200;
BA_ "VFrameFormat" BO_ 2147487251 1;
BA_ "GenMsgSendType" BO_ 2147487251 0;
BA_ "GenMsgCycleTimeFast" BO_ 2147487251 200;
BA_ "GenMsgCycleTime" BO_ 2147487251 200;
BA_ "VFrameFormat" BO_ 2147487252 1;
BA_ "GenMsgSendType" BO_ 2147487252 0;
BA_ "GenMsgCycleTimeFast" BO_ 2147487252 200;
BA_ "GenMsgCycleTime" BO_ 2147487252 200;
BA_ "VFrameFormat" BO_ 2147487253 1;
BA_ "GenMsgSendType" BO_ 2147487253 0;
BA_ "GenMsgCycleTimeFast" BO_ 2147487253 200;
BA_ "GenMsgCycleTime" BO_ 2147487253 200;
BA_ "VFrameFormat" BO_ 2147487254 1;
BA_ "GenMsgSendType" BO_ 2147487254 0;
BA_ "GenMsgCycleTimeFast" BO_ 2147487254 200;
BA_ "GenMsgCycleTime" BO_ 2147487254 200;
BA_ "VFrameFormat" BO_ 2147487255 1;
BA_ "GenMsgSendType" BO_ 2147487255 0;
BA_ "GenMsgCycleTimeFast" BO_ 2147487255 200;
BA_ "GenMsgCycleTime" BO_ 2147487255 200;
BA_ "VFrameFormat" BO_ 2147487256 1;
BA_ "GenMsgSendType" BO_ 2147487256 0;
BA_ "GenMsgCycleTimeFast" BO_ 2147487256 200;
BA_ "GenMsgCycleTime" BO_ 2147487256 200;
BA_ "VFrameFormat" BO_ 2147487257 1;
BA_ "GenMsgSendType" BO_ 2147487257 0;
BA_ "GenMsgCycleTimeFast" BO_ 2147487257 200;
BA_ "GenMsgCycleTime" BO_ 2147487257 200;
BA_ "VFrameFormat" BO_ 2147487258 1;
BA_ "GenMsgSendType" BO_ 2147487258 0;
BA_ "GenMsgCycleTimeFast" BO_ 2147487258 200;
BA_ "GenMsgCycleTime" BO_ 2147487258 200;
BA_ "VFrameFormat" BO_ 2147487259 1;
BA_ "GenMsgSendType" BO_ 2147487259 0;
BA_ "GenMsgCycleTimeFast" BO_ 2147487259 200;
BA_ "GenMsgCycleTime" BO_ 2147487259 200;
BA_ "VFrameFormat" BO_ 2147487260 1;
BA_ "GenMsgSendType" BO_ 2147487260 0;
BA_ "GenMsgCycleTimeFast" BO_ 2147487260 200;
BA_ "GenMsgCycleTime" BO_ 2147487260 200;
BA_ "VFrameFormat" BO_ 2147487261 1;
BA_ "GenMsgSendType" BO_ 2147487261 0;
BA_ "GenMsgCycleTimeFast" BO_ 2147487261 200;
BA_ "GenMsgCycleTime" BO_ 2147487261 200;
BA_ "VFrameFormat" BO_ 2147487262 1;
BA_ "GenMsgSendType" BO_ 2147487262 0;
BA_ "GenMsgCycleTimeFast" BO_ 2147487262 200;
BA_ "GenMsgCycleTime" BO_ 2147487262 200;
BA_ "VFrameFormat" BO_ 2147487263 1;
BA_ "GenMsgSendType" BO_ 2147487263 0;
BA_ "GenMsgCycleTimeFast" BO_ 2147487263 200;
BA_ "GenMsgCycleTime" BO_ 2147487263 200;
BA_ "VFrameFormat" BO_ 2147487264 1;
BA_ "GenMsgSendType" BO_ 2147487264 0;
BA_ "GenMsgCycleTimeFast" BO_ 2147487264 200;
BA_ "GenMsgCycleTime" BO_ 2147487264 200;
BA_ "VFrameFormat" BO_ 2147487265 1;
BA_ "GenMsgSendType" BO_ 2147487265 0;
BA_ "GenMsgCycleTimeFast" BO_ 2147487265 200;
BA_ "GenMsgCycleTime" BO_ 2147487265 200;
BA_ "VFrameFormat" BO_ 2147487266 1;
BA_ "GenMsgSendType" BO_ 2147487266 0;
BA_ "GenMsgCycleTimeFast" BO_ 2147487266 200;
BA_ "GenMsgCycleTime" BO_ 2147487266 200;
BA_ "VFrameFormat" BO_ 2147487267 1;
BA_ "GenMsgSendType" BO_ 2147487267 0;
BA_ "GenMsgCycleTimeFast" BO_ 2147487267 200;
BA_ "GenMsgCycleTime" BO_ 2147487267 200;
BA_ "VFrameFormat" BO_ 2147487488 1;
BA_ "GenMsgSendType" BO_ 2147487488 0;
BA_ "GenMsgCycleTimeFast" BO_ 2147487488 1000;
BA_ "GenMsgCycleTime" BO_ 2147487488 1000;
BA_ "VFrameFormat" BO_ 2147487489 1;
BA_ "GenMsgSendType" BO_ 2147487489 0;
BA_ "GenMsgCycleTimeFast" BO_ 2147487489 1000;
BA_ "GenMsgCycleTime" BO_ 2147487489 1000;
BA_ "VFrameFormat" BO_ 2147487490 1;
BA_ "GenMsgSendType" BO_ 2147487490 0;
BA_ "GenMsgCycleTimeFast" BO_ 2147487490 1000;
BA_ "GenMsgCycleTime" BO_ 2147487490 1000;
BA_ "VFrameFormat" BO_ 2147487491 1;
BA_ "GenMsgSendType" BO_ 2147487491 0;
BA_ "GenMsgCycleTimeFast" BO_ 2147487491 1000;
BA_ "GenMsgCycleTime" BO_ 2147487491 1000;
BA_ "VFrameFormat" BO_ 2147487492 1;
BA_ "GenMsgSendType" BO_ 2147487492 0;
BA_ "GenMsgCycleTimeFast" BO_ 2147487492 1000;
BA_ "GenMsgCycleTime" BO_ 2147487492 1000;
BA_ "VFrameFormat" BO_ 2147487729 1;
BA_ "VFrameFormat" BO_ 2147487730 1;
BA_ "VFrameFormat" BO_ 2147487731 1;
BA_ "GenMsgSendType" BO_ 2147487731 0;
BA_ "GenMsgCycleTime" BO_ 2147487731 100;
BA_ "VFrameFormat" BO_ 2147487732 1;
BA_ "VFrameFormat" BO_ 2147487733 1;
BA_ "VFrameFormat" BO_ 2147487734 1;
BA_ "VFrameFormat" BO_ 2147487735 1;
BA_ "VFrameFormat" BO_ 2147535873 1;
BA_ "GenMsgSendType" BO_ 2147535873 0;
BA_ "GenMsgCycleTime" BO_ 2147535873 100;
BA_ "VFrameFormat" BO_ 2147535876 1;
BA_ "GenMsgSendType" BO_ 2147535876 0;
BA_ "GenMsgCycleTime" BO_ 2147535876 100;
BA_ "VFrameFormat" BO_ 2147535878 1;
BA_ "GenMsgSendType" BO_ 2147535878 0;
BA_ "GenMsgCycleTime" BO_ 2147535878 100;
BA_ "VFrameFormat" BO_ 2147535879 1;
BA_ "GenMsgSendType" BO_ 2147535879 0;
BA_ "GenMsgCycleTime" BO_ 2147535879 100;
BA_ "VFrameFormat" BO_ 2147535880 1;
BA_ "GenMsgSendType" BO_ 2147535880 0;
BA_ "GenMsgCycleTime" BO_ 2147535880 100;
BA_ "VFrameFormat" BO_ 2147535884 1;
BA_ "GenMsgSendType" BO_ 2147535884 0;
BA_ "GenMsgCycleTime" BO_ 2147535884 100;
BA_ "VFrameFormat" BO_ 2147535885 1;
BA_ "GenMsgSendType" BO_ 2147535885 0;
BA_ "GenMsgCycleTime" BO_ 2147535885 100;
BA_ "VFrameFormat" BO_ 2147535886 1;
BA_ "GenMsgSendType" BO_ 2147535886 0;
BA_ "GenMsgCycleTime" BO_ 2147535886 100;
BA_ "VFrameFormat" BO_ 2147535887 1;
BA_ "GenMsgSendType" BO_ 2147535887 0;
BA_ "GenMsgCycleTime" BO_ 2147535887 100;
BA_ "VFrameFormat" BO_ 2147535892 1;
BA_ "GenMsgSendType" BO_ 2147535892 0;
BA_ "GenMsgCycleTime" BO_ 2147535892 100;
BA_ "VFrameFormat" BO_ 2147535893 1;
BA_ "GenMsgSendType" BO_ 2147535893 0;
BA_ "GenMsgCycleTime" BO_ 2147535893 100;
BA_ "VFrameFormat" BO_ 2564429808 1;
BA_ "GenMsgILSupport" BO_ 2564429808 0;
BA_ "VFrameFormat" BO_ 2564429809 1;
BA_ "GenMsgILSupport" BO_ 2564429809 0;
BA_ "VFrameFormat" BO_ 2564432369 1;
BA_ "GenMsgILSupport" BO_ 2564432369 0;
BA_ "VFrameFormat" BO_ 2564481521 1;
BA_ "GenMsgILSupport" BO_ 2564481521 0;
BA_ "VFrameFormat" BO_ 2564485143 1;
BA_ "GenMsgILSupport" BO_ 2564485143 0;
BA_ "VFrameFormat" BO_ 2564485399 1;
BA_ "GenMsgILSupport" BO_ 2564485399 0;
BA_ "VFrameFormat" BO_ 2564485409 1;
BA_ "GenMsgILSupport" BO_ 2564485409 0;
BA_ "VFrameFormat" BO_ 2564485601 1;
BA_ "GenMsgILSupport" BO_ 2564485601 0;
BA_ "GenMsgSendType" BO_ 2566834704 0;
BA_ "GenMsgCycleTime" BO_ 2566834704 1000;
BA_ "VFrameFormat" BO_ 2566834704 3;
BA_ "VFrameFormat" BO_ 2566834721 3;
BA_ "NWM-WakeupAllowed" SG_ 2147484928 N_Gateway 0;
BA_ "GenSigSendType" SG_ 2147484928 N_Gateway 7;
BA_ "NWM-WakeupAllowed" SG_ 2147484929 N_Gateway 0;
BA_ "GenSigSendType" SG_ 2147484929 N_Gateway 7;
BA_ "NWM-WakeupAllowed" SG_ 2147484930 N_Gateway 0;
BA_ "GenSigSendType" SG_ 2147484930 N_Gateway 7;
BA_ "NWM-WakeupAllowed" SG_ 2147484931 N_Gateway 0;
BA_ "GenSigSendType" SG_ 2147484931 N_Gateway 7;
BA_ "NWM-WakeupAllowed" SG_ 2147484932 N_Gateway 0;
BA_ "GenSigSendType" SG_ 2147484932 N_Gateway 7;
BA_ "NWM-WakeupAllowed" SG_ 2147485184 N_Gateway 0;
BA_ "GenSigSendType" SG_ 2147485184 N_Gateway 7;
BA_ "NWM-WakeupAllowed" SG_ 2147486748 X 0;
BA_ "GenSigSendType" SG_ 2147486748 X 7;
BA_ "NWM-WakeupAllowed" SG_ 2147486748 Y 0;
BA_ "GenSigSendType" SG_ 2147486748 Y 7;
BA_ "NWM-WakeupAllowed" SG_ 2147486748 Z 0;
BA_ "GenSigSendType" SG_ 2147486748 Z 7;
BA_ "NWM-WakeupAllowed" SG_ 2147487729 N1_Gateway 0;
BA_ "GenSigSendType" SG_ 2147487729 N1_Gateway 7;
BA_ "NWM-WakeupAllowed" SG_ 2147487729 N2_Gateway 0;
BA_ "GenSigSendType" SG_ 2147487729 N2_Gateway 7;
BA_ "NWM-WakeupAllowed" SG_ 2147487730 N1_Gateway 0;
BA_ "GenSigSendType" SG_ 2147487730 N1_Gateway 7;
BA_ "NWM-WakeupAllowed" SG_ 2147487730 N2_Gateway 0;
BA_ "GenSigSendType" SG_ 2147487730 N2_Gateway 7;
BA_ "NWM-WakeupAllowed" SG_ 2147487731 N1_Gateway 0;
BA_ "GenSigSendType" SG_ 2147487731 N1_Gateway 7;
BA_ "NWM-WakeupAllowed" SG_ 2147487731 N2_Gateway 0;
BA_ "GenSigSendType" SG_ 2147487731 N2_Gateway 7;
BA_ "NWM-WakeupAllowed" SG_ 2147487732 N1_Gateway 0;
BA_ "GenSigSendType" SG_ 2147487732 N1_Gateway 7;
BA_ "NWM-WakeupAllowed" SG_ 2147487732 N2_Gateway 0;
BA_ "GenSigSendType" SG_ 2147487732 N2_Gateway 7;
BA_ "NWM-WakeupAllowed" SG_ 2147487733 N1_Gateway 0;
BA_ "GenSigSendType" SG_ 2147487733 N1_Gateway 7;
BA_ "NWM-WakeupAllowed" SG_ 2147487733 N2_Gateway 0;
BA_ "GenSigSendType" SG_ 2147487733 N2_Gateway 7;
BA_ "NWM-WakeupAllowed" SG_ 2147487734 N1_Gateway 0;
BA_ "GenSigSendType" SG_ 2147487734 N1_Gateway 7;
BA_ "NWM-WakeupAllowed" SG_ 2147487734 N2_Gateway 0;
BA_ "GenSigSendType" SG_ 2147487734 N2_Gateway 7;
BA_ "NWM-WakeupAllowed" SG_ 2147487735 N1_Gateway 0;
BA_ "GenSigSendType" SG_ 2147487735 N1_Gateway 7;
BA_ "NWM-WakeupAllowed" SG_ 2147487735 N2_Gateway 0;
BA_ "GenSigSendType" SG_ 2147487735 N2_Gateway 7;
BA_ "NWM-WakeupAllowed" SG_ 2564429808 N_PDU 0;
BA_ "GenSigSendType" SG_ 2564429808 N_PDU 7;
BA_ "NWM-WakeupAllowed" SG_ 2564429809 N_PDU 0;
BA_ "GenSigSendType" SG_ 2564429809 N_PDU 7;
BA_ "NWM-WakeupAllowed" SG_ 2564432369 N_PDU 0;
BA_ "GenSigSendType" SG_ 2564432369 N_PDU 7;
BA_ "NWM-WakeupAllowed" SG_ 2564481521 N_PDU 0;
BA_ "GenSigSendType" SG_ 2564481521 N_PDU 7;
BA_ "NWM-WakeupAllowed" SG_ 2564485143 N_PDU 0;
BA_ "GenSigSendType" SG_ 2564485143 N_PDU 7;
BA_ "NWM-WakeupAllowed" SG_ 2564485399 N_PDU 0;
BA_ "GenSigSendType" SG_ 2564485399 N_PDU 7;
BA_ "NWM-WakeupAllowed" SG_ 2564485409 N_PDU 0;
BA_ "GenSigSendType" SG_ 2564485409 N_PDU 7;
BA_ "NWM-WakeupAllowed" SG_ 2564485601 N_PDU 0;
BA_ "GenSigSendType" SG_ 2564485601 N_PDU 7;
BA_ "SigType" SG_ 2566834704 AmberWarningLampStatus 5;
BA_ "SPN" SG_ 2566834704 AmberWarningLampStatus 624;
BA_ "SigType" SG_ 2566834704 DTC1 7;
BA_ "SigType" SG_ 2566834704 DTC2 7;
BA_ "SigType" SG_ 2566834704 DTC3 7;
BA_ "SigType" SG_ 2566834704 DTC4 7;
BA_ "SigType" SG_ 2566834704 DTC5 7;
BA_ "SigType" SG_ 2566834704 FlashAmberWarningLamp 5;
BA_ "SPN" SG_ 2566834704 FlashAmberWarningLamp 3040;
BA_ "SigType" SG_ 2566834704 FlashMalfuncIndicatorLamp 5;
BA_ "SPN" SG_ 2566834704 FlashMalfuncIndicatorLamp 3038;
BA_ "SigType" SG_ 2566834704 FlashProtectLamp 5;
BA_ "SPN" SG_ 2566834704 FlashProtectLamp 3041;
BA_ "SigType" SG_ 2566834704 FlashRedStopLamp 5;
BA_ "SPN" SG_ 2566834704 FlashRedStopLamp 3039;
BA_ "SigType" SG_ 2566834704 MalfunctionIndicatorLampStatus 5;
BA_ "SPN" SG_ 2566834704 MalfunctionIndicatorLampStatus 1213;
BA_ "SigType" SG_ 2566834704 ProtectLampStatus 5;
BA_ "SPN" SG_ 2566834704 ProtectLampStatus 987;
BA_ "SigType" SG_ 2566834704 RedStopLampState 4;
BA_ "SPN" SG_ 2566834704 RedStopLampState 623;
BA_ "SigType" SG_ 2566834721 AmberWarningLampStatus 5;
BA_ "SPN" SG_ 2566834721 AmberWarningLampStatus 624;
BA_ "SigType" SG_ 2566834721 DTC1 7;
BA_ "SigType" SG_ 2566834721 DTC2 7;
BA_ "SigType" SG_ 2566834721 DTC3 7;
BA_ "SigType" SG_ 2566834721 DTC4 7;
BA_ "SigType" SG_ 2566834721 DTC5 7;
BA_ "SigType" SG_ 2566834721 FlashAmberWarningLamp 5;
BA_ "SPN" SG_ 2566834721 FlashAmberWarningLamp 3040;
BA_ "SigType" SG_ 2566834721 FlashMalfuncIndicatorLamp 5;
BA_ "SPN" SG_ 2566834721 FlashMalfuncIndicatorLamp 3038;
BA_ "SigType" SG_ 2566834721 FlashProtectLamp 5;
BA_ "SPN" SG_ 2566834721 FlashProtectLamp 3041;
BA_ "SigType" SG_ 2566834721 FlashRedStopLamp 5;
BA_ "SPN" SG_ 2566834721 FlashRedStopLamp 3039;
BA_ "SigType" SG_ 2566834721 MalfunctionIndicatorLampStatus 5;
BA_ "SPN" SG_ 2566834721 MalfunctionIndicatorLampStatus 1213;
BA_ "SigType" SG_ 2566834721 ProtectLampStatus 5;
BA_ "SPN" SG_ 2566834721 ProtectLampStatus 987;
BA_ "SigType" SG_ 2566834721 RedStopLampState 4;
BA_ "SPN" SG_ 2566834721 RedStopLampState 623;
VAL_ 2147486465 WorkingMode 1 "StandAlone" 0 "SimulationMode" ;
VAL_ 2147486467 IN_ANA_08_SWT1 1 "SEL2" 0 "SEL1" ;
VAL_ 2147486467 IN_ANA_09_SWT1 1 "SEL2" 0 "SEL1" ;
VAL_ 2147486467 IN_ANA_10_SWT1 1 "SEL2" 0 "SEL1" ;
VAL_ 2147486467 IN_ANA_11_SWT1 1 "SEL2" 0 "SEL1" ;
VAL_ 2566834704 AmberWarningLampStatus 3 "Not available" 2 "Reserved" 1 "Lamp on" 0 "Lamp off" ;
VAL_ 2566834704 FlashAmberWarningLamp 3 "Unavailable / Do Not Flash" 2 "Reserved" 1 "Fast Flash" 0 "Slow Flash" ;
VAL_ 2566834704 FlashMalfuncIndicatorLamp 3 "Unavailable / Do Not Flash" 2 "Reserved" 1 "Fast Flash" 0 "Slow Flash" ;
VAL_ 2566834704 FlashProtectLamp 3 "Unavailable / Do Not Flash" 2 "Reserved" 1 "Fast Flash" 0 "Slow Flash" ;
VAL_ 2566834704 FlashRedStopLamp 3 "Unavailable / Do Not Flash" 2 "Reserved" 1 "Fast Flash" 0 "Slow Flash" ;
VAL_ 2566834704 MalfunctionIndicatorLampStatus 3 "Not available" 2 "Reserved" 1 "Lamp on" 0 "Lamp off" ;
VAL_ 2566834704 ProtectLampStatus 3 "Not available" 2 "Reserved" 1 "Lamp on" 0 "Lamp off" ;
VAL_ 2566834704 RedStopLampState 3 "Not available" 2 "Reserved" 1 "Lamp on" 0 "Lamp off" ;
VAL_ 2566834721 AmberWarningLampStatus 3 "Not available" 2 "Reserved" 1 "Lamp on" 0 "Lamp off" ;
VAL_ 2566834721 FlashAmberWarningLamp 3 "Unavailable / Do Not Flash" 2 "Reserved" 1 "Fast Flash" 0 "Slow Flash" ;
VAL_ 2566834721 FlashMalfuncIndicatorLamp 3 "Unavailable / Do Not Flash" 2 "Reserved" 1 "Fast Flash" 0 "Slow Flash" ;
VAL_ 2566834721 FlashProtectLamp 3 "Unavailable / Do Not Flash" 2 "Reserved" 1 "Fast Flash" 0 "Slow Flash" ;
VAL_ 2566834721 FlashRedStopLamp 3 "Unavailable / Do Not Flash" 2 "Reserved" 1 "Fast Flash" 0 "Slow Flash" ;
VAL_ 2566834721 MalfunctionIndicatorLampStatus 3 "Not available" 2 "Reserved" 1 "Lamp on" 0 "Lamp off" ;
VAL_ 2566834721 ProtectLampStatus 3 "Not available" 2 "Reserved" 1 "Lamp on" 0 "Lamp off" ;
VAL_ 2566834721 RedStopLampState 3 "Not available" 2 "Reserved" 1 "Lamp on" 0 "Lamp off" ;
